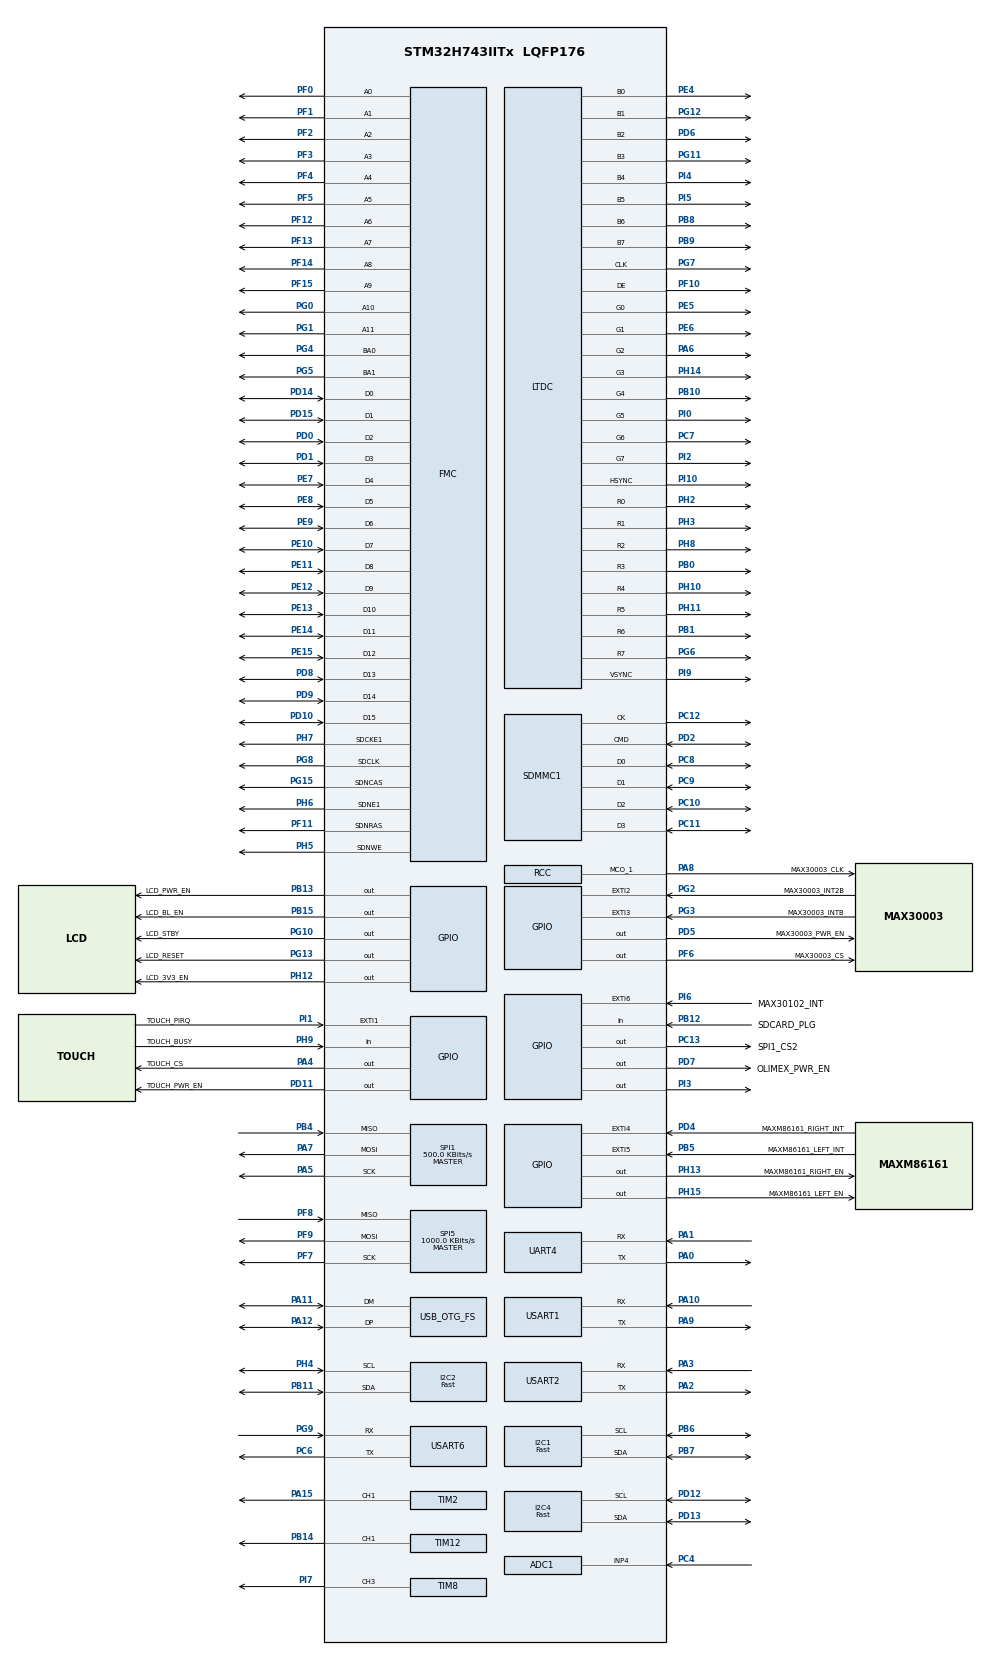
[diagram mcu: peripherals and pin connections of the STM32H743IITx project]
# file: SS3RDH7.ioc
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ADC1.Channel-1\#ChannelRegularConversion=ADC_CHANNEL_4
ADC1.ClockPrescaler=ADC_CLOCK_ASYNC_DIV128
ADC1.EOCSelection=ADC_EOC_SEQ_CONV
ADC1.ExternalTrigConv=ADC_EXTERNALTRIG_T3_TRGO
ADC1.NbrOfConversionFlag=1
ADC1.OffsetNumber-1\#ChannelRegularConversion=ADC_OFFSET_NONE
ADC1.OffsetSignedSaturation-1\#ChannelRegularConversion=DISABLE
ADC1.Rank-1\#ChannelRegularConversion=1
ADC1.SamplingTime-1\#ChannelRegularConversion=ADC_SAMPLETIME_1CYCLE_5
ADC1.master=1
Bdma.I2C4_RX.0.Direction=DMA_PERIPH_TO_MEMORY
Bdma.I2C4_RX.0.EventEnable=DISABLE
Bdma.I2C4_RX.0.Instance=BDMA_Channel0
Bdma.I2C4_RX.0.MemDataAlignment=DMA_MDATAALIGN_BYTE
Bdma.I2C4_RX.0.MemInc=DMA_MINC_ENABLE
Bdma.I2C4_RX.0.Mode=DMA_NORMAL
Bdma.I2C4_RX.0.PeriphDataAlignment=DMA_PDATAALIGN_BYTE
Bdma.I2C4_RX.0.PeriphInc=DMA_PINC_DISABLE
Bdma.I2C4_RX.0.Polarity=HAL_DMAMUX_REQ_GEN_RISING
Bdma.I2C4_RX.0.Priority=DMA_PRIORITY_MEDIUM
Bdma.I2C4_RX.0.RequestNumber=1
Bdma.I2C4_RX.0.SignalID=NONE
Bdma.I2C4_RX.0.SyncEnable=DISABLE
Bdma.I2C4_RX.0.SyncPolarity=HAL_DMAMUX_SYNC_NO_EVENT
Bdma.I2C4_RX.0.SyncRequestNumber=1
Bdma.I2C4_RX.0.SyncSignalID=NONE
Bdma.I2C4_TX.1.Direction=DMA_MEMORY_TO_PERIPH
Bdma.I2C4_TX.1.EventEnable=DISABLE
Bdma.I2C4_TX.1.Instance=BDMA_Channel1
Bdma.I2C4_TX.1.MemDataAlignment=DMA_MDATAALIGN_BYTE
Bdma.I2C4_TX.1.MemInc=DMA_MINC_ENABLE
Bdma.I2C4_TX.1.Mode=DMA_NORMAL
Bdma.I2C4_TX.1.PeriphDataAlignment=DMA_PDATAALIGN_BYTE
Bdma.I2C4_TX.1.PeriphInc=DMA_PINC_DISABLE
Bdma.I2C4_TX.1.Polarity=HAL_DMAMUX_REQ_GEN_RISING
Bdma.I2C4_TX.1.Priority=DMA_PRIORITY_MEDIUM
Bdma.I2C4_TX.1.RequestNumber=1
Bdma.I2C4_TX.1.SignalID=NONE
Bdma.I2C4_TX.1.SyncEnable=DISABLE
Bdma.I2C4_TX.1.SyncPolarity=HAL_DMAMUX_SYNC_NO_EVENT
Bdma.I2C4_TX.1.SyncRequestNumber=1
Bdma.I2C4_TX.1.SyncSignalID=NONE
Bdma.Request0=I2C4_RX
Bdma.Request1=I2C4_TX
Bdma.RequestsNb=2
CORTEX_M7.CPU_DCache=Enabled
CORTEX_M7.CPU_ICache=Enabled
DMA2D.InputAlphaForeground=255
Dma.I2C1_RX.0.Direction=DMA_PERIPH_TO_MEMORY
Dma.I2C1_RX.0.EventEnable=DISABLE
Dma.I2C1_RX.0.FIFOMode=DMA_FIFOMODE_DISABLE
Dma.I2C1_RX.0.Instance=DMA1_Stream0
Dma.I2C1_RX.0.MemDataAlignment=DMA_MDATAALIGN_BYTE
Dma.I2C1_RX.0.MemInc=DMA_MINC_ENABLE
Dma.I2C1_RX.0.Mode=DMA_NORMAL
Dma.I2C1_RX.0.PeriphDataAlignment=DMA_PDATAALIGN_BYTE
Dma.I2C1_RX.0.PeriphInc=DMA_PINC_DISABLE
Dma.I2C1_RX.0.Polarity=HAL_DMAMUX_REQ_GEN_RISING
Dma.I2C1_RX.0.Priority=DMA_PRIORITY_MEDIUM
Dma.I2C1_RX.0.RequestNumber=1
Dma.I2C1_RX.0.SignalID=NONE
Dma.I2C1_RX.0.SyncEnable=DISABLE
Dma.I2C1_RX.0.SyncPolarity=HAL_DMAMUX_SYNC_NO_EVENT
Dma.I2C1_RX.0.SyncRequestNumber=1
Dma.I2C1_RX.0.SyncSignalID=NONE
Dma.I2C1_TX.1.Direction=DMA_MEMORY_TO_PERIPH
Dma.I2C1_TX.1.EventEnable=DISABLE
Dma.I2C1_TX.1.FIFOMode=DMA_FIFOMODE_DISABLE
Dma.I2C1_TX.1.Instance=DMA1_Stream1
Dma.I2C1_TX.1.MemDataAlignment=DMA_MDATAALIGN_BYTE
Dma.I2C1_TX.1.MemInc=DMA_MINC_ENABLE
Dma.I2C1_TX.1.Mode=DMA_NORMAL
Dma.I2C1_TX.1.PeriphDataAlignment=DMA_PDATAALIGN_BYTE
Dma.I2C1_TX.1.PeriphInc=DMA_PINC_DISABLE
Dma.I2C1_TX.1.Polarity=HAL_DMAMUX_REQ_GEN_RISING
Dma.I2C1_TX.1.Priority=DMA_PRIORITY_MEDIUM
Dma.I2C1_TX.1.RequestNumber=1
Dma.I2C1_TX.1.SignalID=NONE
Dma.I2C1_TX.1.SyncEnable=DISABLE
Dma.I2C1_TX.1.SyncPolarity=HAL_DMAMUX_SYNC_NO_EVENT
Dma.I2C1_TX.1.SyncRequestNumber=1
Dma.I2C1_TX.1.SyncSignalID=NONE
Dma.I2C2_RX.2.Direction=DMA_PERIPH_TO_MEMORY
Dma.I2C2_RX.2.EventEnable=DISABLE
Dma.I2C2_RX.2.FIFOMode=DMA_FIFOMODE_DISABLE
Dma.I2C2_RX.2.Instance=DMA1_Stream2
Dma.I2C2_RX.2.MemDataAlignment=DMA_MDATAALIGN_BYTE
Dma.I2C2_RX.2.MemInc=DMA_MINC_ENABLE
Dma.I2C2_RX.2.Mode=DMA_NORMAL
Dma.I2C2_RX.2.PeriphDataAlignment=DMA_PDATAALIGN_BYTE
Dma.I2C2_RX.2.PeriphInc=DMA_PINC_DISABLE
Dma.I2C2_RX.2.Polarity=HAL_DMAMUX_REQ_GEN_RISING
Dma.I2C2_RX.2.Priority=DMA_PRIORITY_MEDIUM
Dma.I2C2_RX.2.RequestNumber=1
Dma.I2C2_RX.2.SignalID=NONE
Dma.I2C2_RX.2.SyncEnable=DISABLE
Dma.I2C2_RX.2.SyncPolarity=HAL_DMAMUX_SYNC_NO_EVENT
Dma.I2C2_RX.2.SyncRequestNumber=1
Dma.I2C2_RX.2.SyncSignalID=NONE
Dma.I2C2_TX.3.Direction=DMA_MEMORY_TO_PERIPH
Dma.I2C2_TX.3.EventEnable=DISABLE
Dma.I2C2_TX.3.FIFOMode=DMA_FIFOMODE_DISABLE
Dma.I2C2_TX.3.Instance=DMA1_Stream3
Dma.I2C2_TX.3.MemDataAlignment=DMA_MDATAALIGN_BYTE
Dma.I2C2_TX.3.MemInc=DMA_MINC_ENABLE
Dma.I2C2_TX.3.Mode=DMA_NORMAL
Dma.I2C2_TX.3.PeriphDataAlignment=DMA_PDATAALIGN_BYTE
Dma.I2C2_TX.3.PeriphInc=DMA_PINC_DISABLE
Dma.I2C2_TX.3.Polarity=HAL_DMAMUX_REQ_GEN_RISING
Dma.I2C2_TX.3.Priority=DMA_PRIORITY_MEDIUM
Dma.I2C2_TX.3.RequestNumber=1
Dma.I2C2_TX.3.SignalID=NONE
Dma.I2C2_TX.3.SyncEnable=DISABLE
Dma.I2C2_TX.3.SyncPolarity=HAL_DMAMUX_SYNC_NO_EVENT
Dma.I2C2_TX.3.SyncRequestNumber=1
Dma.I2C2_TX.3.SyncSignalID=NONE
Dma.Request0=I2C1_RX
Dma.Request1=I2C1_TX
Dma.Request10=USART6_RX
Dma.Request11=USART6_TX
Dma.Request12=SPI1_RX
Dma.Request13=SPI1_TX
Dma.Request14=SPI5_RX
Dma.Request15=SPI5_TX
Dma.Request2=I2C2_RX
Dma.Request3=I2C2_TX
Dma.Request4=UART4_RX
Dma.Request5=UART4_TX
Dma.Request6=USART2_RX
Dma.Request7=USART2_TX
Dma.Request8=USART1_RX
Dma.Request9=USART1_TX
Dma.SPI1_RX.12.Direction=DMA_PERIPH_TO_MEMORY
Dma.SPI1_RX.12.EventEnable=DISABLE
Dma.SPI1_RX.12.FIFOMode=DMA_FIFOMODE_DISABLE
Dma.SPI1_RX.12.Instance=DMA2_Stream4
Dma.SPI1_RX.12.MemDataAlignment=DMA_MDATAALIGN_BYTE
Dma.SPI1_RX.12.MemInc=DMA_MINC_ENABLE
Dma.SPI1_RX.12.Mode=DMA_NORMAL
Dma.SPI1_RX.12.PeriphDataAlignment=DMA_PDATAALIGN_BYTE
Dma.SPI1_RX.12.PeriphInc=DMA_PINC_DISABLE
Dma.SPI1_RX.12.Polarity=HAL_DMAMUX_REQ_GEN_RISING
Dma.SPI1_RX.12.Priority=DMA_PRIORITY_MEDIUM
Dma.SPI1_RX.12.RequestNumber=1
Dma.SPI1_RX.12.SignalID=NONE
Dma.SPI1_RX.12.SyncEnable=DISABLE
Dma.SPI1_RX.12.SyncPolarity=HAL_DMAMUX_SYNC_NO_EVENT
Dma.SPI1_RX.12.SyncRequestNumber=1
Dma.SPI1_RX.12.SyncSignalID=NONE
Dma.SPI1_TX.13.Direction=DMA_MEMORY_TO_PERIPH
Dma.SPI1_TX.13.EventEnable=DISABLE
Dma.SPI1_TX.13.FIFOMode=DMA_FIFOMODE_DISABLE
Dma.SPI1_TX.13.Instance=DMA2_Stream5
Dma.SPI1_TX.13.MemDataAlignment=DMA_MDATAALIGN_BYTE
Dma.SPI1_TX.13.MemInc=DMA_MINC_ENABLE
Dma.SPI1_TX.13.Mode=DMA_NORMAL
Dma.SPI1_TX.13.PeriphDataAlignment=DMA_PDATAALIGN_BYTE
Dma.SPI1_TX.13.PeriphInc=DMA_PINC_DISABLE
Dma.SPI1_TX.13.Polarity=HAL_DMAMUX_REQ_GEN_RISING
Dma.SPI1_TX.13.Priority=DMA_PRIORITY_MEDIUM
Dma.SPI1_TX.13.RequestNumber=1
Dma.SPI1_TX.13.SignalID=NONE
Dma.SPI1_TX.13.SyncEnable=DISABLE
Dma.SPI1_TX.13.SyncPolarity=HAL_DMAMUX_SYNC_NO_EVENT
Dma.SPI1_TX.13.SyncRequestNumber=1
Dma.SPI1_TX.13.SyncSignalID=NONE
Dma.SPI5_RX.14.Direction=DMA_PERIPH_TO_MEMORY
Dma.SPI5_RX.14.EventEnable=DISABLE
Dma.SPI5_RX.14.FIFOMode=DMA_FIFOMODE_DISABLE
Dma.SPI5_RX.14.Instance=DMA2_Stream6
Dma.SPI5_RX.14.MemDataAlignment=DMA_MDATAALIGN_BYTE
Dma.SPI5_RX.14.MemInc=DMA_MINC_ENABLE
Dma.SPI5_RX.14.Mode=DMA_NORMAL
Dma.SPI5_RX.14.PeriphDataAlignment=DMA_PDATAALIGN_BYTE
Dma.SPI5_RX.14.PeriphInc=DMA_PINC_DISABLE
Dma.SPI5_RX.14.Polarity=HAL_DMAMUX_REQ_GEN_RISING
Dma.SPI5_RX.14.Priority=DMA_PRIORITY_MEDIUM
Dma.SPI5_RX.14.RequestNumber=1
Dma.SPI5_RX.14.SignalID=NONE
Dma.SPI5_RX.14.SyncEnable=DISABLE
Dma.SPI5_RX.14.SyncPolarity=HAL_DMAMUX_SYNC_NO_EVENT
Dma.SPI5_RX.14.SyncRequestNumber=1
Dma.SPI5_RX.14.SyncSignalID=NONE
Dma.SPI5_TX.15.Direction=DMA_MEMORY_TO_PERIPH
Dma.SPI5_TX.15.EventEnable=DISABLE
Dma.SPI5_TX.15.FIFOMode=DMA_FIFOMODE_DISABLE
Dma.SPI5_TX.15.Instance=DMA2_Stream7
Dma.SPI5_TX.15.MemDataAlignment=DMA_MDATAALIGN_BYTE
Dma.SPI5_TX.15.MemInc=DMA_MINC_ENABLE
Dma.SPI5_TX.15.Mode=DMA_NORMAL
Dma.SPI5_TX.15.PeriphDataAlignment=DMA_PDATAALIGN_BYTE
Dma.SPI5_TX.15.PeriphInc=DMA_PINC_DISABLE
Dma.SPI5_TX.15.Polarity=HAL_DMAMUX_REQ_GEN_RISING
Dma.SPI5_TX.15.Priority=DMA_PRIORITY_MEDIUM
Dma.SPI5_TX.15.RequestNumber=1
Dma.SPI5_TX.15.SignalID=NONE
Dma.SPI5_TX.15.SyncEnable=DISABLE
Dma.SPI5_TX.15.SyncPolarity=HAL_DMAMUX_SYNC_NO_EVENT
Dma.SPI5_TX.15.SyncRequestNumber=1
Dma.SPI5_TX.15.SyncSignalID=NONE
Dma.UART4_RX.4.Direction=DMA_PERIPH_TO_MEMORY
Dma.UART4_RX.4.EventEnable=DISABLE
Dma.UART4_RX.4.FIFOMode=DMA_FIFOMODE_DISABLE
Dma.UART4_RX.4.Instance=DMA1_Stream4
Dma.UART4_RX.4.MemDataAlignment=DMA_MDATAALIGN_BYTE
Dma.UART4_RX.4.MemInc=DMA_MINC_ENABLE
Dma.UART4_RX.4.Mode=DMA_NORMAL
Dma.UART4_RX.4.PeriphDataAlignment=DMA_PDATAALIGN_BYTE
Dma.UART4_RX.4.PeriphInc=DMA_PINC_DISABLE
Dma.UART4_RX.4.Polarity=HAL_DMAMUX_REQ_GEN_RISING
Dma.UART4_RX.4.Priority=DMA_PRIORITY_LOW
Dma.UART4_RX.4.RequestNumber=1
Dma.UART4_RX.4.SignalID=NONE
Dma.UART4_RX.4.SyncEnable=DISABLE
Dma.UART4_RX.4.SyncPolarity=HAL_DMAMUX_SYNC_NO_EVENT
Dma.UART4_RX.4.SyncRequestNumber=1
Dma.UART4_RX.4.SyncSignalID=NONE
Dma.UART4_TX.5.Direction=DMA_MEMORY_TO_PERIPH
Dma.UART4_TX.5.EventEnable=DISABLE
Dma.UART4_TX.5.FIFOMode=DMA_FIFOMODE_DISABLE
Dma.UART4_TX.5.Instance=DMA1_Stream5
Dma.UART4_TX.5.MemDataAlignment=DMA_MDATAALIGN_BYTE
Dma.UART4_TX.5.MemInc=DMA_MINC_ENABLE
Dma.UART4_TX.5.Mode=DMA_NORMAL
Dma.UART4_TX.5.PeriphDataAlignment=DMA_PDATAALIGN_BYTE
Dma.UART4_TX.5.PeriphInc=DMA_PINC_DISABLE
Dma.UART4_TX.5.Polarity=HAL_DMAMUX_REQ_GEN_RISING
Dma.UART4_TX.5.Priority=DMA_PRIORITY_LOW
Dma.UART4_TX.5.RequestNumber=1
Dma.UART4_TX.5.SignalID=NONE
Dma.UART4_TX.5.SyncEnable=DISABLE
Dma.UART4_TX.5.SyncPolarity=HAL_DMAMUX_SYNC_NO_EVENT
Dma.UART4_TX.5.SyncRequestNumber=1
Dma.UART4_TX.5.SyncSignalID=NONE
Dma.USART1_RX.8.Direction=DMA_PERIPH_TO_MEMORY
Dma.USART1_RX.8.EventEnable=DISABLE
Dma.USART1_RX.8.FIFOMode=DMA_FIFOMODE_DISABLE
Dma.USART1_RX.8.Instance=DMA2_Stream0
Dma.USART1_RX.8.MemDataAlignment=DMA_MDATAALIGN_BYTE
Dma.USART1_RX.8.MemInc=DMA_MINC_ENABLE
Dma.USART1_RX.8.Mode=DMA_NORMAL
Dma.USART1_RX.8.PeriphDataAlignment=DMA_PDATAALIGN_BYTE
Dma.USART1_RX.8.PeriphInc=DMA_PINC_DISABLE
Dma.USART1_RX.8.Polarity=HAL_DMAMUX_REQ_GEN_RISING
Dma.USART1_RX.8.Priority=DMA_PRIORITY_MEDIUM
Dma.USART1_RX.8.RequestNumber=1
Dma.USART1_RX.8.SignalID=NONE
Dma.USART1_RX.8.SyncEnable=DISABLE
Dma.USART1_RX.8.SyncPolarity=HAL_DMAMUX_SYNC_NO_EVENT
Dma.USART1_RX.8.SyncRequestNumber=1
Dma.USART1_RX.8.SyncSignalID=NONE
Dma.USART1_TX.9.Direction=DMA_MEMORY_TO_PERIPH
Dma.USART1_TX.9.EventEnable=DISABLE
Dma.USART1_TX.9.FIFOMode=DMA_FIFOMODE_DISABLE
Dma.USART1_TX.9.Instance=DMA2_Stream1
Dma.USART1_TX.9.MemDataAlignment=DMA_MDATAALIGN_BYTE
Dma.USART1_TX.9.MemInc=DMA_MINC_ENABLE
Dma.USART1_TX.9.Mode=DMA_NORMAL
Dma.USART1_TX.9.PeriphDataAlignment=DMA_PDATAALIGN_BYTE
Dma.USART1_TX.9.PeriphInc=DMA_PINC_DISABLE
Dma.USART1_TX.9.Polarity=HAL_DMAMUX_REQ_GEN_RISING
Dma.USART1_TX.9.Priority=DMA_PRIORITY_MEDIUM
Dma.USART1_TX.9.RequestNumber=1
Dma.USART1_TX.9.SignalID=NONE
Dma.USART1_TX.9.SyncEnable=DISABLE
Dma.USART1_TX.9.SyncPolarity=HAL_DMAMUX_SYNC_NO_EVENT
Dma.USART1_TX.9.SyncRequestNumber=1
Dma.USART1_TX.9.SyncSignalID=NONE
Dma.USART2_RX.6.Direction=DMA_PERIPH_TO_MEMORY
Dma.USART2_RX.6.EventEnable=DISABLE
Dma.USART2_RX.6.FIFOMode=DMA_FIFOMODE_DISABLE
Dma.USART2_RX.6.Instance=DMA1_Stream6
Dma.USART2_RX.6.MemDataAlignment=DMA_MDATAALIGN_BYTE
Dma.USART2_RX.6.MemInc=DMA_MINC_ENABLE
Dma.USART2_RX.6.Mode=DMA_NORMAL
Dma.USART2_RX.6.PeriphDataAlignment=DMA_PDATAALIGN_BYTE
Dma.USART2_RX.6.PeriphInc=DMA_PINC_DISABLE
Dma.USART2_RX.6.Polarity=HAL_DMAMUX_REQ_GEN_RISING
Dma.USART2_RX.6.Priority=DMA_PRIORITY_LOW
Dma.USART2_RX.6.RequestNumber=1
Dma.USART2_RX.6.SignalID=NONE
Dma.USART2_RX.6.SyncEnable=DISABLE
Dma.USART2_RX.6.SyncPolarity=HAL_DMAMUX_SYNC_NO_EVENT
Dma.USART2_RX.6.SyncRequestNumber=1
Dma.USART2_RX.6.SyncSignalID=NONE
Dma.USART2_TX.7.Direction=DMA_MEMORY_TO_PERIPH
Dma.USART2_TX.7.EventEnable=DISABLE
Dma.USART2_TX.7.FIFOMode=DMA_FIFOMODE_DISABLE
Dma.USART2_TX.7.Instance=DMA1_Stream7
Dma.USART2_TX.7.MemDataAlignment=DMA_MDATAALIGN_BYTE
Dma.USART2_TX.7.MemInc=DMA_MINC_ENABLE
Dma.USART2_TX.7.Mode=DMA_NORMAL
Dma.USART2_TX.7.PeriphDataAlignment=DMA_PDATAALIGN_BYTE
Dma.USART2_TX.7.PeriphInc=DMA_PINC_DISABLE
Dma.USART2_TX.7.Polarity=HAL_DMAMUX_REQ_GEN_RISING
Dma.USART2_TX.7.Priority=DMA_PRIORITY_LOW
Dma.USART2_TX.7.RequestNumber=1
Dma.USART2_TX.7.SignalID=NONE
Dma.USART2_TX.7.SyncEnable=DISABLE
Dma.USART2_TX.7.SyncPolarity=HAL_DMAMUX_SYNC_NO_EVENT
Dma.USART2_TX.7.SyncRequestNumber=1
Dma.USART2_TX.7.SyncSignalID=NONE
Dma.USART6_RX.10.Direction=DMA_PERIPH_TO_MEMORY
Dma.USART6_RX.10.EventEnable=DISABLE
Dma.USART6_RX.10.FIFOMode=DMA_FIFOMODE_DISABLE
Dma.USART6_RX.10.Instance=DMA2_Stream2
Dma.USART6_RX.10.MemDataAlignment=DMA_MDATAALIGN_BYTE
Dma.USART6_RX.10.MemInc=DMA_MINC_ENABLE
Dma.USART6_RX.10.Mode=DMA_NORMAL
Dma.USART6_RX.10.PeriphDataAlignment=DMA_PDATAALIGN_BYTE
Dma.USART6_RX.10.PeriphInc=DMA_PINC_DISABLE
Dma.USART6_RX.10.Polarity=HAL_DMAMUX_REQ_GEN_RISING
Dma.USART6_RX.10.Priority=DMA_PRIORITY_LOW
Dma.USART6_RX.10.RequestNumber=1
Dma.USART6_RX.10.SignalID=NONE
Dma.USART6_RX.10.SyncEnable=DISABLE
Dma.USART6_RX.10.SyncPolarity=HAL_DMAMUX_SYNC_NO_EVENT
Dma.USART6_RX.10.SyncRequestNumber=1
Dma.USART6_RX.10.SyncSignalID=NONE
Dma.USART6_TX.11.Direction=DMA_MEMORY_TO_PERIPH
Dma.USART6_TX.11.EventEnable=DISABLE
Dma.USART6_TX.11.FIFOMode=DMA_FIFOMODE_DISABLE
Dma.USART6_TX.11.Instance=DMA2_Stream3
Dma.USART6_TX.11.MemDataAlignment=DMA_MDATAALIGN_BYTE
Dma.USART6_TX.11.MemInc=DMA_MINC_ENABLE
Dma.USART6_TX.11.Mode=DMA_NORMAL
Dma.USART6_TX.11.PeriphDataAlignment=DMA_PDATAALIGN_BYTE
Dma.USART6_TX.11.PeriphInc=DMA_PINC_DISABLE
Dma.USART6_TX.11.Polarity=HAL_DMAMUX_REQ_GEN_RISING
Dma.USART6_TX.11.Priority=DMA_PRIORITY_LOW
Dma.USART6_TX.11.RequestNumber=1
Dma.USART6_TX.11.SignalID=NONE
Dma.USART6_TX.11.SyncEnable=DISABLE
Dma.USART6_TX.11.SyncPolarity=HAL_DMAMUX_SYNC_NO_EVENT
Dma.USART6_TX.11.SyncRequestNumber=1
Dma.USART6_TX.11.SyncSignalID=NONE
FATFS.BSP.number=1
FATFS._MAX_SS=4096
FATFS0.BSP.STBoard=false
FATFS0.BSP.api=Unknown
FATFS0.BSP.i2caddr=0
FATFS0.BSP.instance=PB12
FATFS0.BSP.ip=GPIO
FATFS0.BSP.mode=Input
FATFS0.BSP.name=Detect_SDIO
FATFS0.BSP.solution=PB12
FMC.CASLatency1=FMC_SDRAM_CAS_LATENCY_3
FMC.ExitSelfRefreshDelay1=7
FMC.LoadToActiveDelay1=2
FMC.RCDDelay1=2
FMC.RPDelay1=2
FMC.RPDelay2=2
FMC.ReadBurst1=FMC_SDRAM_RBURST_ENABLE
FMC.ReadBurst2=FMC_SDRAM_RBURST_ENABLE
FMC.ReadPipeDelay1=FMC_SDRAM_RPIPE_DELAY_2
FMC.ReadPipeDelay2=FMC_SDRAM_RPIPE_DELAY_2
FMC.RowCycleDelay1=6
FMC.RowCycleDelay2=6
FMC.SDClockPeriod1=FMC_SDRAM_CLOCK_PERIOD_2
FMC.SDClockPeriod2=FMC_SDRAM_CLOCK_PERIOD_2
FMC.SelfRefreshTime1=4
FMC.WriteRecoveryTime1=2
FREERTOS.Tasks01=defaultTask,24,1024,StartDefaultTask,Default,NULL,Dynamic,NULL,NULL;touchTask,24,1024,StartTouchTask,Default,NULL,Dynamic,NULL,NULL;touchIRQTask,24,1024,StartTouchIRQTask,Default,NULL,Dynamic,NULL,NULL;max30003Task,24,1024,StartMAX30003Task,Default,NULL,Dynamic,NULL,NULL;max30003IRQTask,24,1024,StartMAX30003IRQTask,Default,NULL,Dynamic,NULL,NULL;max30102Task,8,1024,StartMAX30102Task,Default,NULL,Dynamic,NULL,NULL;max30102IRQTask,24,1024,StartMAX30102IRQTask,Default,NULL,Dynamic,NULL,NULL;maxm86161RTask,24,1024,StartMAXM86161RTask,Default,NULL,Dynamic,NULL,NULL;maxm86161IRTask,24,1024,StartMAXM86161IRQRTask,Default,NULL,Dynamic,NULL,NULL;maxm86161LTask,24,1024,StartMAXM86161LTask,Default,NULL,Dynamic,NULL,NULL;maxm86161ILTask,24,1024,StartMAXM86161IRQLTask,Default,NULL,Dynamic,NULL,NULL;i2c1TxTask,24,1024,StartI2C1TxTask,Default,NULL,Dynamic,NULL,NULL;i2c1RxTask,24,1024,StartI2C1RxTask,Default,NULL,Dynamic,NULL,NULL;i2c1ErrorTask,24,1024,StartI2C1ErrorTask,Default,NULL,Dynamic,NULL,NULL;i2c2TxTask,24,1024,StartI2C2TxTask,Default,NULL,Dynamic,NULL,NULL;i2c2RxTask,24,1024,StartI2C2RxTask,Default,NULL,Dynamic,NULL,NULL;i2c2ErrorTask,24,1024,StartI2C2ErrorTask,Default,NULL,Dynamic,NULL,NULL;debugTask,24,1024,StartDebugTask,Default,NULL,Dynamic,NULL,NULL;fatFsTask,24,1024,StartFatFsTask,Default,NULL,Dynamic,NULL,NULL;usbTask,24,1024,StartUsbTask,Default,NULL,Dynamic,NULL,NULL;usbDmaTxTask,24,1024,StartUsbDmaTxTask,Default,NULL,Dynamic,NULL,NULL;usbDmaRxTask,24,1024,StartUsbDmaRxTask,Default,NULL,Dynamic,NULL,NULL;i2c4TxTask,24,1024,StartI2C4TxTask,Default,NULL,Dynamic,NULL,NULL;i2c4RxTask,8,1024,StartI2C4RxTask,Default,NULL,Dynamic,NULL,NULL;i2c4ErrorTask,8,1024,StartI2C4ErrorTask,Default,NULL,Dynamic,NULL,NULL
FREERTOS.configENABLE_FPU=1
FREERTOS.configMINIMAL_STACK_SIZE=1024
FREERTOS.configTOTAL_HEAP_SIZE=159744
FREERTOS.configUSE_DAEMON_TASK_STARTUP_HOOK=1
FREERTOS.configUSE_IDLE_HOOK=1
FREERTOS.configUSE_MALLOC_FAILED_HOOK=1
FREERTOS.configUSE_STATS_FORMATTING_FUNCTIONS=1
FREERTOS.configUSE_TICK_HOOK=1
I2C1.I2C_Speed_Mode=I2C_Fast
I2C1.Timing=0x00B03FDB
I2C2.I2C_Speed_Mode=I2C_Fast
I2C2.Timing=0x00B03FDB
I2C4.I2C_Speed_Mode=I2C_Fast
I2C4.Timing=0x00B03FDB
LTDC.ActiveW=800
LTDC.Alpha0_L0=255
LTDC.Alpha0_L1=255
LTDC.Alpha_L0=255
LTDC.Alpha_L1=255
LTDC.FBStartAdress_L0=0xD0000000
LTDC.FBStartAdress_L1=0xD0119400
LTDC.HBP=40
LTDC.HFP=40
LTDC.HSync=48
LTDC.ImageHeight_L0=480
LTDC.ImageHeight_L1=480
LTDC.ImageWidth_L0=800
LTDC.Layers=0
LTDC.PixelFormat_L0=LTDC_PIXEL_FORMAT_RGB888
LTDC.VBP=29
LTDC.VFP=13
LTDC.VSync=3
LTDC.WindowX1_L0=800
LTDC.WindowX1_L1=800
LTDC.WindowY1_L0=480
LTDC.WindowY1_L1=480
Mcu.Family=STM32H7
Mcu.Name=STM32H743IITx
Mcu.Package=LQFP176
NVIC.ADC_IRQn=true\:5\:0\:false\:false\:true\:true\:true\:true
NVIC.BDMA_Channel0_IRQn=true\:5\:0\:false\:false\:true\:true\:false\:true
NVIC.BDMA_Channel1_IRQn=true\:5\:0\:false\:false\:true\:true\:false\:true
NVIC.DMA1_Stream0_IRQn=true\:5\:0\:false\:false\:true\:true\:false\:true
NVIC.DMA1_Stream1_IRQn=true\:5\:0\:false\:false\:true\:true\:false\:true
NVIC.DMA1_Stream2_IRQn=true\:5\:0\:false\:false\:true\:true\:false\:true
NVIC.DMA1_Stream3_IRQn=true\:5\:0\:false\:false\:true\:true\:false\:true
NVIC.DMA1_Stream4_IRQn=true\:5\:0\:false\:false\:true\:true\:false\:true
NVIC.DMA1_Stream5_IRQn=true\:5\:0\:false\:false\:true\:true\:false\:true
NVIC.DMA1_Stream6_IRQn=true\:5\:0\:false\:false\:true\:true\:false\:true
NVIC.DMA1_Stream7_IRQn=true\:5\:0\:false\:false\:true\:true\:false\:true
NVIC.DMA2D_IRQn=true\:5\:0\:false\:false\:true\:false\:true\:true
NVIC.DMA2_Stream0_IRQn=true\:5\:0\:false\:false\:true\:true\:false\:true
NVIC.DMA2_Stream1_IRQn=true\:5\:0\:false\:false\:true\:true\:false\:true
NVIC.DMA2_Stream2_IRQn=true\:5\:0\:false\:false\:true\:true\:false\:true
NVIC.DMA2_Stream3_IRQn=true\:5\:0\:false\:false\:true\:true\:false\:true
NVIC.DMA2_Stream4_IRQn=true\:5\:0\:false\:false\:true\:true\:false\:true
NVIC.DMA2_Stream5_IRQn=true\:5\:0\:false\:false\:true\:true\:false\:true
NVIC.DMA2_Stream6_IRQn=true\:5\:0\:false\:false\:true\:true\:false\:true
NVIC.DMA2_Stream7_IRQn=true\:5\:0\:false\:false\:true\:true\:false\:true
NVIC.EXTI1_IRQn=true\:5\:0\:false\:false\:true\:true\:true\:true
NVIC.EXTI2_IRQn=true\:5\:0\:false\:false\:true\:true\:true\:true
NVIC.EXTI3_IRQn=true\:5\:0\:false\:false\:true\:true\:true\:true
NVIC.EXTI4_IRQn=true\:5\:0\:false\:false\:true\:true\:true\:true
NVIC.EXTI9_5_IRQn=true\:5\:0\:false\:false\:true\:true\:true\:true
NVIC.FPU_IRQn=true\:5\:0\:false\:false\:true\:true\:true\:false
NVIC.I2C1_ER_IRQn=true\:5\:0\:false\:false\:true\:true\:true\:true
NVIC.I2C1_EV_IRQn=true\:5\:0\:false\:false\:true\:true\:true\:true
NVIC.I2C2_ER_IRQn=true\:5\:0\:false\:false\:true\:true\:true\:true
NVIC.I2C2_EV_IRQn=true\:5\:0\:false\:false\:true\:true\:true\:true
NVIC.I2C4_ER_IRQn=true\:5\:0\:false\:false\:true\:true\:true\:true
NVIC.I2C4_EV_IRQn=true\:5\:0\:false\:false\:true\:true\:true\:true
NVIC.JPEG_IRQn=true\:5\:0\:false\:false\:true\:true\:true\:true
NVIC.LTDC_ER_IRQn=true\:5\:0\:false\:false\:true\:true\:true\:true
NVIC.LTDC_IRQn=true\:5\:0\:false\:false\:true\:true\:true\:true
NVIC.OTG_FS_EP1_IN_IRQn=true\:5\:0\:false\:false\:true\:true\:true\:true
NVIC.OTG_FS_EP1_OUT_IRQn=true\:5\:0\:false\:false\:true\:true\:true\:true
NVIC.OTG_FS_IRQn=true\:5\:0\:false\:false\:true\:true\:false\:true
NVIC.PriorityGroup=NVIC_PRIORITYGROUP_4
NVIC.SDMMC1_IRQn=true\:5\:0\:false\:false\:true\:true\:true\:true
NVIC.SPI1_IRQn=true\:5\:0\:false\:false\:true\:false\:false\:true
NVIC.SPI5_IRQn=true\:5\:0\:false\:false\:true\:false\:false\:true
NVIC.TIM6_DAC_IRQn=true\:0\:0\:false\:false\:true\:false\:false\:true
NVIC.TimeBase=TIM6_DAC_IRQn
NVIC.TimeBaseIP=TIM6
NVIC.UART4_IRQn=true\:5\:0\:false\:false\:true\:true\:true\:true
NVIC.USART1_IRQn=true\:5\:0\:false\:false\:true\:true\:true\:true
NVIC.USART2_IRQn=true\:5\:0\:false\:false\:true\:true\:true\:true
NVIC.USART6_IRQn=true\:5\:0\:false\:false\:true\:true\:true\:true
PA0.GPIO_Speed=GPIO_SPEED_FREQ_VERY_HIGH
PA0.Mode=Asynchronous
PA0.Signal=UART4_TX
PA1.GPIO_Speed=GPIO_SPEED_FREQ_VERY_HIGH
PA1.Mode=Asynchronous
PA1.Signal=UART4_RX
PA10.GPIO_Speed=GPIO_SPEED_FREQ_VERY_HIGH
PA10.Mode=Asynchronous
PA10.Signal=USART1_RX
PA11.GPIO_Speed=GPIO_SPEED_FREQ_VERY_HIGH
PA11.Mode=Device_Only
PA11.Signal=USB_OTG_FS_DM
PA12.GPIO_Speed=GPIO_SPEED_FREQ_VERY_HIGH
PA12.Mode=Device_Only
PA12.Signal=USB_OTG_FS_DP
PA13\ (JTMS/SWDIO).Mode=Trace_Asynchronous_SW
PA13\ (JTMS/SWDIO).Signal=DEBUG_JTMS-SWDIO
PA14\ (JTCK/SWCLK).Mode=Trace_Asynchronous_SW
PA14\ (JTCK/SWCLK).Signal=DEBUG_JTCK-SWCLK
PA15\ (JTDI).Signal=S_TIM2_CH1
PA2.GPIO_Speed=GPIO_SPEED_FREQ_VERY_HIGH
PA2.Mode=Asynchronous
PA2.Signal=USART2_TX
PA3.GPIO_Speed=GPIO_SPEED_FREQ_VERY_HIGH
PA3.Mode=Asynchronous
PA3.Signal=USART2_RX
PA4.GPIO_Label=TOUCH_CS
PA4.GPIO_PuPd=GPIO_PULLUP
PA4.GPIO_Speed=GPIO_SPEED_FREQ_VERY_HIGH
PA4.PinState=GPIO_PIN_SET
PA4.Signal=GPIO_Output
PA5.GPIO_PuPd=GPIO_PULLUP
PA5.GPIO_Speed=GPIO_SPEED_FREQ_VERY_HIGH
PA5.Mode=Full_Duplex_Master
PA5.Signal=SPI1_SCK
PA6.GPIO_Speed=GPIO_SPEED_FREQ_VERY_HIGH
PA6.Mode=RGB888
PA6.Signal=LTDC_G2
PA7.GPIO_PuPd=GPIO_PULLUP
PA7.GPIO_Speed=GPIO_SPEED_FREQ_VERY_HIGH
PA7.Mode=Full_Duplex_Master
PA7.Signal=SPI1_MOSI
PA8.GPIO_Label=MAX30003_CLK
PA8.Mode=Clock-out-1
PA8.Signal=RCC_MCO_1
PA9.GPIO_Speed=GPIO_SPEED_FREQ_VERY_HIGH
PA9.Mode=Asynchronous
PA9.Signal=USART1_TX
PB0.GPIO_Speed=GPIO_SPEED_FREQ_VERY_HIGH
PB0.Mode=RGB888
PB0.Signal=LTDC_R3
PB1.GPIO_Speed=GPIO_SPEED_FREQ_VERY_HIGH
PB1.Mode=RGB888
PB1.Signal=LTDC_R6
PB10.GPIO_Speed=GPIO_SPEED_FREQ_VERY_HIGH
PB10.Mode=RGB888
PB10.Signal=LTDC_G4
PB11.GPIO_Speed=GPIO_SPEED_FREQ_VERY_HIGH
PB11.Mode=I2C
PB11.Signal=I2C2_SDA
PB12.GPIO_Label=SDCARD_PLG
PB12.GPIO_PuPd=GPIO_PULLUP
PB12.Signal=GPIO_Input
PB13.GPIO_Label=LCD_PWR_EN
PB13.GPIO_PuPd=GPIO_PULLUP
PB13.Signal=GPIO_Output
PB14.GPIO_Speed=GPIO_SPEED_FREQ_VERY_HIGH
PB14.Signal=S_TIM12_CH1
PB15.GPIO_Label=LCD_BL_EN
PB15.GPIO_PuPd=GPIO_PULLUP
PB15.Signal=GPIO_Output
PB3\ (JTDO/TRACESWO).Mode=Trace_Asynchronous_SW
PB3\ (JTDO/TRACESWO).Signal=DEBUG_JTDO-SWO
PB4\ (NJTRST).GPIO_PuPd=GPIO_PULLUP
PB4\ (NJTRST).GPIO_Speed=GPIO_SPEED_FREQ_VERY_HIGH
PB4\ (NJTRST).Mode=Full_Duplex_Master
PB4\ (NJTRST).Signal=SPI1_MISO
PB5.GPIO_Label=MAXM86161_LEFT_INT
PB5.GPIO_ModeDefaultEXTI=GPIO_MODE_IT_FALLING
PB5.GPIO_PuPd=GPIO_PULLUP
PB5.Signal=GPXTI5
PB6.GPIO_Speed=GPIO_SPEED_FREQ_VERY_HIGH
PB6.Mode=I2C
PB6.Signal=I2C1_SCL
PB7.GPIO_Speed=GPIO_SPEED_FREQ_VERY_HIGH
PB7.Mode=I2C
PB7.Signal=I2C1_SDA
PB8.GPIO_Speed=GPIO_SPEED_FREQ_VERY_HIGH
PB8.Mode=RGB888
PB8.Signal=LTDC_B6
PB9.GPIO_Speed=GPIO_SPEED_FREQ_VERY_HIGH
PB9.Mode=RGB888
PB9.Signal=LTDC_B7
PC0.Signal=ADCx_INP10
PC10.Mode=SD_4_bits_Wide_bus
PC10.Signal=SDMMC1_D2
PC11.Mode=SD_4_bits_Wide_bus
PC11.Signal=SDMMC1_D3
PC12.Mode=SD_4_bits_Wide_bus
PC12.Signal=SDMMC1_CK
PC13.GPIO_Label=SPI1_CS2
PC13.GPIO_PuPd=GPIO_PULLUP
PC13.PinState=GPIO_PIN_SET
PC13.Signal=GPIO_Output
PC14-OSC32_IN\ (OSC32_IN).Mode=LSE-External-Oscillator
PC14-OSC32_IN\ (OSC32_IN).Signal=RCC_OSC32_IN
PC15-OSC32_OUT\ (OSC32_OUT).Mode=LSE-External-Oscillator
PC15-OSC32_OUT\ (OSC32_OUT).Signal=RCC_OSC32_OUT
PC4.Signal=ADCx_INP4
PC6.GPIO_Speed=GPIO_SPEED_FREQ_VERY_HIGH
PC6.Mode=Asynchronous
PC6.Signal=USART6_TX
PC7.GPIO_Speed=GPIO_SPEED_FREQ_VERY_HIGH
PC7.Mode=RGB888
PC7.Signal=LTDC_G6
PC8.Mode=SD_4_bits_Wide_bus
PC8.Signal=SDMMC1_D0
PC9.Mode=SD_4_bits_Wide_bus
PC9.Signal=SDMMC1_D1
PD0.Signal=FMC_D2_DA2
PD1.Signal=FMC_D3_DA3
PD10.Signal=FMC_D15_DA15
PD11.GPIO_Label=TOUCH_PWR_EN
PD11.GPIO_PuPd=GPIO_PULLUP
PD11.GPIO_Speed=GPIO_SPEED_FREQ_VERY_HIGH
PD11.PinState=GPIO_PIN_SET
PD11.Signal=GPIO_Output
PD12.GPIO_Speed=GPIO_SPEED_FREQ_VERY_HIGH
PD12.Mode=I2C
PD12.Signal=I2C4_SCL
PD13.GPIO_Speed=GPIO_SPEED_FREQ_VERY_HIGH
PD13.Mode=I2C
PD13.Signal=I2C4_SDA
PD14.Signal=FMC_D0_DA0
PD15.Signal=FMC_D1_DA1
PD2.Mode=SD_4_bits_Wide_bus
PD2.Signal=SDMMC1_CMD
PD4.GPIO_Label=MAXM86161_RIGHT_INT
PD4.GPIO_ModeDefaultEXTI=GPIO_MODE_IT_FALLING
PD4.GPIO_PuPd=GPIO_PULLUP
PD4.Signal=GPXTI4
PD5.GPIO_Label=MAX30003_PWR_EN
PD5.Signal=GPIO_Output
PD6.GPIO_Speed=GPIO_SPEED_FREQ_VERY_HIGH
PD6.Mode=RGB888
PD6.Signal=LTDC_B2
PD7.GPIO_Label=OLIMEX_PWR_EN
PD7.GPIO_Speed=GPIO_SPEED_FREQ_VERY_HIGH
PD7.Signal=GPIO_Output
PD8.Signal=FMC_D13_DA13
PD9.Signal=FMC_D14_DA14
PE0.Signal=FMC_NBL0
PE1.Signal=FMC_NBL1
PE10.Signal=FMC_D7_DA7
PE11.Signal=FMC_D8_DA8
PE12.Signal=FMC_D9_DA9
PE13.Signal=FMC_D10_DA10
PE14.Signal=FMC_D11_DA11
PE15.Signal=FMC_D12_DA12
PE4.GPIO_Speed=GPIO_SPEED_FREQ_VERY_HIGH
PE4.Mode=RGB888
PE4.Signal=LTDC_B0
PE5.GPIO_Speed=GPIO_SPEED_FREQ_VERY_HIGH
PE5.Mode=RGB888
PE5.Signal=LTDC_G0
PE6.GPIO_Speed=GPIO_SPEED_FREQ_VERY_HIGH
PE6.Mode=RGB888
PE6.Signal=LTDC_G1
PE7.Signal=FMC_D4_DA4
PE8.Signal=FMC_D5_DA5
PE9.Signal=FMC_D6_DA6
PF0.Signal=FMC_A0
PF1.Signal=FMC_A1
PF10.GPIO_Speed=GPIO_SPEED_FREQ_VERY_HIGH
PF10.Mode=RGB888
PF10.Signal=LTDC_DE
PF11.Signal=FMC_SDNRAS
PF12.Signal=FMC_A6
PF13.Signal=FMC_A7
PF14.Signal=FMC_A8
PF15.Signal=FMC_A9
PF2.Signal=FMC_A2
PF3.Signal=FMC_A3
PF4.Signal=FMC_A4
PF5.Signal=FMC_A5
PF6.GPIO_Label=MAX30003_CS
PF6.GPIO_PuPd=GPIO_PULLUP
PF6.GPIO_Speed=GPIO_SPEED_FREQ_VERY_HIGH
PF6.PinState=GPIO_PIN_SET
PF6.Signal=GPIO_Output
PF7.GPIO_PuPd=GPIO_PULLUP
PF7.GPIO_Speed=GPIO_SPEED_FREQ_VERY_HIGH
PF7.Mode=Full_Duplex_Master
PF7.Signal=SPI5_SCK
PF8.GPIO_PuPd=GPIO_PULLUP
PF8.GPIO_Speed=GPIO_SPEED_FREQ_VERY_HIGH
PF8.Mode=Full_Duplex_Master
PF8.Signal=SPI5_MISO
PF9.GPIO_PuPd=GPIO_PULLUP
PF9.GPIO_Speed=GPIO_SPEED_FREQ_VERY_HIGH
PF9.Mode=Full_Duplex_Master
PF9.Signal=SPI5_MOSI
PG0.Signal=FMC_A10
PG1.Signal=FMC_A11
PG10.GPIO_Label=LCD_STBY
PG10.GPIO_PuPd=GPIO_PULLUP
PG10.GPIO_Speed=GPIO_SPEED_FREQ_VERY_HIGH
PG10.PinState=GPIO_PIN_SET
PG10.Signal=GPIO_Output
PG11.GPIO_Speed=GPIO_SPEED_FREQ_VERY_HIGH
PG11.Mode=RGB888
PG11.Signal=LTDC_B3
PG12.GPIO_Speed=GPIO_SPEED_FREQ_VERY_HIGH
PG12.Mode=RGB888
PG12.Signal=LTDC_B1
PG13.GPIO_Label=LCD_RESET
PG13.GPIO_PuPd=GPIO_PULLUP
PG13.GPIO_Speed=GPIO_SPEED_FREQ_VERY_HIGH
PG13.PinState=GPIO_PIN_SET
PG13.Signal=GPIO_Output
PG15.Signal=FMC_SDNCAS
PG2.GPIO_Label=MAX30003_INT2B
PG2.GPIO_PuPd=GPIO_PULLUP
PG2.Signal=GPXTI2
PG3.GPIO_Label=MAX30003_INTB
PG3.GPIO_PuPd=GPIO_PULLUP
PG3.Signal=GPXTI3
PG4.Signal=FMC_A14_BA0
PG5.Signal=FMC_A15_BA1
PG6.GPIO_Speed=GPIO_SPEED_FREQ_VERY_HIGH
PG6.Mode=RGB888
PG6.Signal=LTDC_R7
PG7.GPIO_Speed=GPIO_SPEED_FREQ_VERY_HIGH
PG7.Mode=RGB888
PG7.Signal=LTDC_CLK
PG8.Signal=FMC_SDCLK
PG9.GPIO_Speed=GPIO_SPEED_FREQ_VERY_HIGH
PG9.Mode=Asynchronous
PG9.Signal=USART6_RX
PH0-OSC_IN\ (PH0).Mode=HSE-External-Oscillator
PH0-OSC_IN\ (PH0).Signal=RCC_OSC_IN
PH1-OSC_OUT\ (PH1).Mode=HSE-External-Oscillator
PH1-OSC_OUT\ (PH1).Signal=RCC_OSC_OUT
PH10.GPIO_Speed=GPIO_SPEED_FREQ_VERY_HIGH
PH10.Mode=RGB888
PH10.Signal=LTDC_R4
PH11.GPIO_Speed=GPIO_SPEED_FREQ_VERY_HIGH
PH11.Mode=RGB888
PH11.Signal=LTDC_R5
PH12.GPIO_Label=LCD_3V3_EN
PH12.GPIO_PuPd=GPIO_PULLUP
PH12.GPIO_Speed=GPIO_SPEED_FREQ_VERY_HIGH
PH12.PinState=GPIO_PIN_SET
PH12.Signal=GPIO_Output
PH13.GPIO_Label=MAXM86161_RIGHT_EN
PH13.GPIO_PuPd=GPIO_NOPULL
PH13.GPIO_Speed=GPIO_SPEED_FREQ_VERY_HIGH
PH13.PinState=GPIO_PIN_SET
PH13.Signal=GPIO_Output
PH14.GPIO_Speed=GPIO_SPEED_FREQ_VERY_HIGH
PH14.Mode=RGB888
PH14.Signal=LTDC_G3
PH15.GPIO_Label=MAXM86161_LEFT_EN
PH15.GPIO_Speed=GPIO_SPEED_FREQ_VERY_HIGH
PH15.PinState=GPIO_PIN_SET
PH15.Signal=GPIO_Output
PH2.GPIO_Speed=GPIO_SPEED_FREQ_VERY_HIGH
PH2.Mode=RGB888
PH2.Signal=LTDC_R0
PH3.GPIO_Speed=GPIO_SPEED_FREQ_VERY_HIGH
PH3.Mode=RGB888
PH3.Signal=LTDC_R1
PH4.GPIO_Speed=GPIO_SPEED_FREQ_VERY_HIGH
PH4.Mode=I2C
PH4.Signal=I2C2_SCL
PH5.Signal=FMC_SDNWE
PH6.Mode=SdramChipSelect2_1
PH6.Signal=FMC_SDNE1
PH7.Mode=SdramChipSelect2_1
PH7.Signal=FMC_SDCKE1
PH8.GPIO_Speed=GPIO_SPEED_FREQ_VERY_HIGH
PH8.Mode=RGB888
PH8.Signal=LTDC_R2
PH9.GPIO_Label=TOUCH_BUSY
PH9.GPIO_PuPd=GPIO_NOPULL
PH9.Signal=GPIO_Input
PI0.GPIO_Speed=GPIO_SPEED_FREQ_VERY_HIGH
PI0.Mode=RGB888
PI0.Signal=LTDC_G5
PI1.GPIO_Label=TOUCH_PIRQ
PI1.GPIO_ModeDefaultEXTI=GPIO_MODE_IT_FALLING
PI1.GPIO_PuPd=GPIO_PULLUP
PI1.Signal=GPXTI1
PI10.GPIO_Speed=GPIO_SPEED_FREQ_VERY_HIGH
PI10.Mode=RGB888
PI10.Signal=LTDC_HSYNC
PI2.GPIO_Speed=GPIO_SPEED_FREQ_VERY_HIGH
PI2.Mode=RGB888
PI2.Signal=LTDC_G7
PI3.Signal=GPIO_Output
PI4.GPIO_Speed=GPIO_SPEED_FREQ_VERY_HIGH
PI4.Mode=RGB888
PI4.Signal=LTDC_B4
PI5.GPIO_Speed=GPIO_SPEED_FREQ_VERY_HIGH
PI5.Mode=RGB888
PI5.Signal=LTDC_B5
PI6.GPIO_Label=MAX30102_INT
PI6.GPIO_PuPd=GPIO_PULLUP
PI6.Signal=GPXTI6
PI7.Signal=S_TIM8_CH3
PI9.GPIO_Speed=GPIO_SPEED_FREQ_VERY_HIGH
PI9.Mode=RGB888
PI9.Signal=LTDC_VSYNC
ProjectManager.HeapSize=0x3E00
ProjectManager.StackSize=0x3E00
ProjectManager.TargetToolchain=STM32CubeIDE
RCC.ADCFreq_Value=128000000
RCC.APB1Freq_Value=120000000
RCC.APB2Freq_Value=120000000
RCC.APB3Freq_Value=120000000
RCC.APB4Freq_Value=120000000
RCC.CKPERSourceSelection=RCC_CLKPSOURCE_HSE
RCC.CortexFreq_Value=480000000
RCC.D1PPRE=RCC_APB3_DIV2
RCC.D2PPRE1=RCC_APB1_DIV2
RCC.D2PPRE2=RCC_APB2_DIV2
RCC.D3PPRE=RCC_APB4_DIV2
RCC.DIVM1=1
RCC.DIVM2=8
RCC.DIVM3=8
RCC.DIVN1=120
RCC.DIVN2=256
RCC.DIVN3=192
RCC.DIVP3=4
RCC.DIVQ3=4
RCC.DIVR3=10
RCC.HCLKFreq_Value=240000000
RCC.HPRE=RCC_HCLK_DIV2
RCC.HSE_VALUE=8000000
RCC.PLL1_VCI_Range-AdvancedSettings=RCC_PLL1VCIRANGE_0
RCC.PLL2FRACN=0
RCC.PLL3FRACN=0
RCC.PLLFRACN=0
RCC.PLLSourceVirtual=RCC_PLLSOURCE_HSE
RCC.RCC_MCO1Source=RCC_MCO1SOURCE_LSE
RCC.RTCClockSelection=RCC_RTCCLKSOURCE_LSE
RCC.SPI123CLockSelection=RCC_SPI123CLKSOURCE_PLL2
RCC.SYSCLKFreq_VALUE=480000000
RCC.SYSCLKSource=RCC_SYSCLKSOURCE_PLLCLK
RCC.Spi45ClockSelection=RCC_SPI45CLKSOURCE_PLL2
RCC.USBCLockSelection=RCC_USBCLKSOURCE_PLL3
RCC.USBFreq_Value=48000000
SDMMC1.ClockDiv=20
SH.ADCx_INP10.0=ADC1_INP10
SH.ADCx_INP4.0=ADC1_INP4,IN4-Single-Ended
SH.FMC_A0.0=FMC_A0,12b-sda1
SH.FMC_A1.0=FMC_A1,12b-sda1
SH.FMC_A10.0=FMC_A10,12b-sda1
SH.FMC_A11.0=FMC_A11,12b-sda1
SH.FMC_A14_BA0.0=FMC_BA0,FourSdramBanks1
SH.FMC_A15_BA1.0=FMC_BA1,FourSdramBanks1
SH.FMC_A2.0=FMC_A2,12b-sda1
SH.FMC_A3.0=FMC_A3,12b-sda1
SH.FMC_A4.0=FMC_A4,12b-sda1
SH.FMC_A5.0=FMC_A5,12b-sda1
SH.FMC_A6.0=FMC_A6,12b-sda1
SH.FMC_A7.0=FMC_A7,12b-sda1
SH.FMC_A8.0=FMC_A8,12b-sda1
SH.FMC_A9.0=FMC_A9,12b-sda1
SH.FMC_D0_DA0.0=FMC_D0,sd-16b-d1
SH.FMC_D10_DA10.0=FMC_D10,sd-16b-d1
SH.FMC_D11_DA11.0=FMC_D11,sd-16b-d1
SH.FMC_D12_DA12.0=FMC_D12,sd-16b-d1
SH.FMC_D13_DA13.0=FMC_D13,sd-16b-d1
SH.FMC_D14_DA14.0=FMC_D14,sd-16b-d1
SH.FMC_D15_DA15.0=FMC_D15,sd-16b-d1
SH.FMC_D1_DA1.0=FMC_D1,sd-16b-d1
SH.FMC_D2_DA2.0=FMC_D2,sd-16b-d1
SH.FMC_D3_DA3.0=FMC_D3,sd-16b-d1
SH.FMC_D4_DA4.0=FMC_D4,sd-16b-d1
SH.FMC_D5_DA5.0=FMC_D5,sd-16b-d1
SH.FMC_D6_DA6.0=FMC_D6,sd-16b-d1
SH.FMC_D7_DA7.0=FMC_D7,sd-16b-d1
SH.FMC_D8_DA8.0=FMC_D8,sd-16b-d1
SH.FMC_D9_DA9.0=FMC_D9,sd-16b-d1
SH.FMC_NBL0.0=FMC_NBL0
SH.FMC_NBL1.0=FMC_NBL1
SH.FMC_SDCLK.0=FMC_SDCLK,12b-sda1
SH.FMC_SDNCAS.0=FMC_SDNCAS,12b-sda1
SH.FMC_SDNRAS.0=FMC_SDNRAS,12b-sda1
SH.FMC_SDNWE.0=FMC_SDNWE,12b-sda1
SH.S_TIM12_CH1.0=TIM12_CH1,PWM Generation1 CH1
SH.S_TIM2_CH1.0=TIM2_CH1,Output Compare1 CH1
SH.S_TIM8_CH3.0=TIM8_CH3,Output Compare3 CH3
SPI1.BaudRatePrescaler=SPI_BAUDRATEPRESCALER_256
SPI1.CalculateBaudRate=500.0 KBits/s
SPI1.DataSize=SPI_DATASIZE_8BIT
SPI1.Direction=SPI_DIRECTION_2LINES
SPI1.Mode=SPI_MODE_MASTER
SPI1.VirtualType=VM_MASTER
SPI5.BaudRatePrescaler=SPI_BAUDRATEPRESCALER_128
SPI5.CalculateBaudRate=1000.0 KBits/s
SPI5.DataSize=SPI_DATASIZE_8BIT
SPI5.Direction=SPI_DIRECTION_2LINES
SPI5.Mode=SPI_MODE_MASTER
SPI5.VirtualType=VM_MASTER
STMicroelectronics.X-CUBE-TOUCHGFX.4.15.0.ApplicationCcGraphicsJjApplication=TouchGFXOoGenerator
STMicroelectronics.X-CUBE-TOUCHGFX.4.15.0.tgfx_address1=0xD0000000
STMicroelectronics.X-CUBE-TOUCHGFX.4.15.0.tgfx_address2=0xD0119600
STMicroelectronics.X-CUBE-TOUCHGFX.4.15.0.tgfx_buffering_strategy=Double
STMicroelectronics.X-CUBE-TOUCHGFX.4.15.0.tgfx_display_interface=disp_ltdc
STMicroelectronics.X-CUBE-TOUCHGFX.4.15.0.tgfx_hardware_accelerator=dma_2d
STMicroelectronics.X-CUBE-TOUCHGFX.4.15.0.tgfx_location=By Address
STMicroelectronics.X-CUBE-TOUCHGFX.4.15.0.tgfx_vsync=vsync_ltdc
TIM12.Channel-PWM\ Generation1\ CH1=TIM_CHANNEL_1
TIM12.ClockDivision=TIM_CLOCKDIVISION_DIV4
TIM12.OCPolarity_1=TIM_OCPOLARITY_LOW
TIM12.Period=999
TIM12.Prescaler=59
TIM12.Pulse-PWM\ Generation1\ CH1=499
TIM13.Channel=TIM_CHANNEL_1
TIM13.ClockDivision=TIM_CLOCKDIVISION_DIV4
TIM13.Period=999
TIM13.Prescaler=59
TIM2.Channel-Output\ Compare1\ CH1=TIM_CHANNEL_1
TIM2.OCPolarity_1=TIM_OCPOLARITY_LOW
TIM2.Period=0
TIM2.Prescaler=119
TIM3.Channel-Output\ Compare1\ No\ Output=TIM_CHANNEL_1
TIM3.ClockDivision=TIM_CLOCKDIVISION_DIV4
TIM3.Period=4
TIM3.Prescaler=14999
TIM3.TIM_MasterOutputTrigger=TIM_TRGO_UPDATE
TIM7.Period=99
TIM7.Prescaler=44999
TIM7.TIM_MasterOutputTrigger=TIM_TRGO_UPDATE
TIM8.Channel-Output\ Compare3\ CH3=TIM_CHANNEL_3
TIM8.OCPolarity_3=TIM_OCPOLARITY_LOW
TIM8.Period=0
TIM8.Prescaler=119
USART1.VirtualMode-Asynchronous=VM_ASYNC
USART2.VirtualMode-Asynchronous=VM_ASYNC
USART6.VirtualMode-Asynchronous=VM_ASYNC
USB_DEVICE.CLASS_NAME_FS=MSC
USB_DEVICE.MANUFACTURER_STRING-MSC_FS=Hardway Industries
USB_DEVICE.PRODUCT_STRING_MSC_FS=SS3RDH7
USB_DEVICE.VirtualMode-MSC_FS=Msc
USB_DEVICE.VirtualModeFS=Msc_FS
USB_OTG_FS.VirtualMode=Device_Only
USB_OTG_FS.dma_enable=ENABLE
VP_CRC_VS_CRC.Mode=CRC_Activate
VP_DMA2D_VS_DMA2D.Mode=DMA2D_Activate
VP_FATFS_VS_SDIO.Mode=SDIO
VP_FREERTOS_VS_CMSIS_V2.Mode=CMSIS_V2
VP_JPEG_VS_JPEG.Mode=JPEG_Activate
VP_LIBJPEG_VS_JPEGLIB.Mode=Enabled
VP_RTC_VS_RTC_Activate.Mode=RTC_Enabled
VP_RTC_VS_RTC_Calendar.Mode=RTC_Calendar
VP_STMicroelectronics.X-CUBE-TOUCHGFX_VS_GraphicsJjApplication_4.15.0.Mode=GraphicsJjApplication
VP_SYS_VS_tim6.Mode=TIM6
VP_TIM13_VS_ClockSourceINT.Mode=Enable_Timer
VP_TIM13_VS_no_output1.Mode=Output Compare1 No Output
VP_TIM3_VS_ClockSourceINT.Mode=Internal
VP_TIM3_VS_no_output1.Mode=Output Compare1 No Output
VP_TIM7_VS_ClockSourceINT.Mode=Enable_Timer
VP_USB_DEVICE_VS_USB_DEVICE_MSC_FS.Mode=MSC_FS
board=custom

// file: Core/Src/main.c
/* USER CODE BEGIN Header */
/**
  ******************************************************************************
  * @file           : main.c
  * @brief          : Main program body
  ******************************************************************************
  * @attention
  *
  * <h2><center>&copy; Copyright (c) 2020 STMicroelectronics.
  * All rights reserved.</center></h2>
  *
  * This software component is licensed by ST under Ultimate Liberty license
  * SLA0044, the "License"; You may not use this file except in compliance with
  * the License. You may obtain a copy of the License at:
  *                             www.st.com/SLA0044
  *
  ******************************************************************************
  */
/* USER CODE END Header */
#include "main.h"
#include "cmsis_os.h"
#include "adc.h"
#include "bdma.h"
#include "crc.h"
#include "dma.h"
#include "dma2d.h"
#include "fatfs.h"
#include "i2c.h"
#include "jpeg.h"
#include "libjpeg.h"
#include "ltdc.h"
#include "rtc.h"
#include "sdmmc.h"
#include "spi.h"
#include "tim.h"
#include "usart.h"
#include "usb_device.h"
#include "gpio.h"
#include "fmc.h"
#include "app_touchgfx.h"

/* USER CODE BEGIN Includes */
#include <stdio.h>
#include "display/display.h"
#include "devices/touch/XPT2046.h"
#include "devices/touch/XPT2046LL.h"
#include "devices/ecg/MAX30003LL.h"
#include "devices/ppg/MAX30102LL.h"
#include "devices/ppg/MAX86161LL.h"
/* USER CODE END Includes */

void SystemClock_Config(void);
void MX_FREERTOS_Init(void);
/* USER CODE BEGIN PFP */
TouchEvent_t event;
extern osThreadId touchEventTaskHandle;
/* USER CODE END PFP */

/* USER CODE BEGIN 0 */
void xpt2046TouchEventCallback(TouchEvent_t* e) {
    event.xPosition = e->xPosition;
    event.yPosition = e->yPosition;
    event.batteryVoltage = e->batteryVoltage;
    event.auxValue = e->auxValue;
    event.temperature = e->temperature;
    event.z1Position = e->z1Position;
    event.z2Position = e->z2Position;
    osThreadResume(touchEventTaskHandle);
}

void HAL_SPI_TxRxCpltCallback(SPI_HandleTypeDef *hspi) {
	if(hspi->Instance == SPI1) {
		xpt2046LowLevelSpiTxRxHandler(hspi);
	} else if(hspi->Instance == SPI5) {
		max30003LowLevelSpiTxRxHandler(hspi);
	}
}

int _write(int file, char *ptr, int len) {
	for(int i = 0; i < len; i++) {
		ITM_SendChar(ptr[i]);
	}
	return len;
}
/* USER CODE END 0 */

int main(void)
{

  /* Enable I-Cache---------------------------------------------------------*/
  SCB_EnableICache();

  /* Enable D-Cache---------------------------------------------------------*/
  //SCB_EnableDCache();

  /* MCU Configuration--------------------------------------------------------*/

  /* Reset of all peripherals, Initializes the Flash interface and the Systick. */
  HAL_Init();

  /* Configure the system clock */
  SystemClock_Config();

  /* Initialize all configured peripherals */
  MX_GPIO_Init();
  MX_BDMA_Init();
  MX_DMA_Init();
  MX_DMA2D_Init();
  MX_FMC_Init();
  SDRAM_InitSequence();
  MX_I2C1_Init();
  MX_I2C2_Init();
  MX_LTDC_Init();
  MX_SDMMC1_SD_Init();
  MX_SPI1_Init();
  MX_SPI5_Init();
  MX_UART4_Init();
  MX_USART1_UART_Init();
  MX_USART2_UART_Init();
  MX_USART6_UART_Init();
  MX_FATFS_Init();
  MX_LIBJPEG_Init();
  MX_JPEG_Init();
  MX_ADC1_Init();
  MX_CRC_Init();
  MX_RTC_Init();
  MX_TIM3_Init();
  MX_TIM7_Init();
  MX_TIM12_Init();
  MX_TIM13_Init();
  MX_I2C4_Init();
  MX_TIM2_Init();
  MX_TIM8_Init();
  MX_TouchGFX_Init();
  /* USER CODE BEGIN 2 */
  HAL_Delay(100);
  HAL_GPIO_WritePin(GPIOD, MAX30003_PWR_EN_Pin|OLIMEX_PWR_EN_Pin, GPIO_PIN_SET);
  HAL_TIM_Base_Start(&htim3);
  HAL_TIM_Base_Start_IT(&htim7);
  HAL_TIM_PWM_Start(&htim12, TIM_CHANNEL_1);
  HAL_ADC_Start_IT(&hadc1);

  //HAL_TIM_Base_Start(&htim2);
  //HAL_TIM_Base_Start(&htim8);

  HAL_TIM_OC_Start(&htim2, TIM_CHANNEL_1);
  HAL_TIM_OC_Start(&htim8, TIM_CHANNEL_3);
  /* USER CODE END 2 */

  /* Init scheduler */
  osKernelInitialize();  /* Call init function for freertos objects (in freertos.c) */
  MX_FREERTOS_Init();
  /* Start scheduler */
  osKernelStart();

  /* We should never get here as control is now taken by the scheduler */
  /* Infinite loop */
  while (1)
  {

  }
}

void SystemClock_Config(void)
{
  RCC_OscInitTypeDef RCC_OscInitStruct = {0};
  RCC_ClkInitTypeDef RCC_ClkInitStruct = {0};
  RCC_PeriphCLKInitTypeDef PeriphClkInitStruct = {0};

  /** Supply configuration update enable
  */
  HAL_PWREx_ConfigSupply(PWR_LDO_SUPPLY);
  /** Configure the main internal regulator output voltage
  */
  __HAL_PWR_VOLTAGESCALING_CONFIG(PWR_REGULATOR_VOLTAGE_SCALE0);

  while(!__HAL_PWR_GET_FLAG(PWR_FLAG_VOSRDY)) {}
  /** Configure LSE Drive Capability
  */
  HAL_PWR_EnableBkUpAccess();
  //__HAL_RCC_LSEDRIVE_CONFIG(RCC_LSEDRIVE_LOW);
#if RTC_CLOCK_SOURCE == RTC_CLOCK_SOURCE_LSE
  //__HAL_RCC_LSEDRIVE_CONFIG(RCC_LSEDRIVE_LOW);
  //__HAL_RCC_LSEDRIVE_CONFIG(RCC_LSEDRIVE_MEDIUMLOW);
  //__HAL_RCC_LSEDRIVE_CONFIG(RCC_LSEDRIVE_MEDIUMHIGH);
  __HAL_RCC_LSEDRIVE_CONFIG(RCC_LSEDRIVE_HIGH);
#endif
  /** Macro to configure the PLL clock source
  */
  __HAL_RCC_PLL_PLLSOURCE_CONFIG(RCC_PLLSOURCE_HSE);
  /** Initializes the RCC Oscillators according to the specified parameters
  * in the RCC_OscInitTypeDef structure.
  */
  RCC_OscInitStruct.OscillatorType = RCC_OSCILLATORTYPE_HSE;
#if RTC_CLOCK_SOURCE == RTC_CLOCK_SOURCE_LSE
  RCC_OscInitStruct.OscillatorType |= RCC_OSCILLATORTYPE_LSE;//|RCC_OSCILLATORTYPE_LSE;
  RCC_OscInitStruct.LSEState = RCC_LSE_ON;
#else
  RCC_OscInitStruct.OscillatorType |= RCC_OSCILLATORTYPE_LSI;
#endif
  RCC_OscInitStruct.HSEState = RCC_HSE_ON;
  RCC_OscInitStruct.LSEState = RCC_LSI_ON;
  RCC_OscInitStruct.PLL.PLLState = RCC_PLL_ON;
  RCC_OscInitStruct.PLL.PLLSource = RCC_PLLSOURCE_HSE;
  RCC_OscInitStruct.PLL.PLLM = 1;
  RCC_OscInitStruct.PLL.PLLN = 120;
  RCC_OscInitStruct.PLL.PLLP = 2;
  RCC_OscInitStruct.PLL.PLLQ = 2;
  RCC_OscInitStruct.PLL.PLLR = 2;
  RCC_OscInitStruct.PLL.PLLRGE = RCC_PLL1VCIRANGE_3;
  RCC_OscInitStruct.PLL.PLLVCOSEL = RCC_PLL1VCOWIDE;
  RCC_OscInitStruct.PLL.PLLFRACN = 0;
  if (HAL_RCC_OscConfig(&RCC_OscInitStruct) != HAL_OK)
  {
    Error_Handler();
  }
  /** Initializes the CPU, AHB and APB buses clocks
  */
  RCC_ClkInitStruct.ClockType = RCC_CLOCKTYPE_HCLK|RCC_CLOCKTYPE_SYSCLK
                              |RCC_CLOCKTYPE_PCLK1|RCC_CLOCKTYPE_PCLK2
                              |RCC_CLOCKTYPE_D3PCLK1|RCC_CLOCKTYPE_D1PCLK1;
  RCC_ClkInitStruct.SYSCLKSource = RCC_SYSCLKSOURCE_PLLCLK;
  RCC_ClkInitStruct.SYSCLKDivider = RCC_SYSCLK_DIV1;
  RCC_ClkInitStruct.AHBCLKDivider = RCC_HCLK_DIV2;
  RCC_ClkInitStruct.APB3CLKDivider = RCC_APB3_DIV2;
  RCC_ClkInitStruct.APB1CLKDivider = RCC_APB1_DIV2;
  RCC_ClkInitStruct.APB2CLKDivider = RCC_APB2_DIV2;
  RCC_ClkInitStruct.APB4CLKDivider = RCC_APB4_DIV2;

  if (HAL_RCC_ClockConfig(&RCC_ClkInitStruct, FLASH_LATENCY_4) != HAL_OK)
  {
    Error_Handler();
  }
  PeriphClkInitStruct.PeriphClockSelection = RCC_PERIPHCLK_RTC|RCC_PERIPHCLK_LTDC
                              |RCC_PERIPHCLK_USART2|RCC_PERIPHCLK_UART4
                              |RCC_PERIPHCLK_USART6|RCC_PERIPHCLK_USART1
                              |RCC_PERIPHCLK_SPI5|RCC_PERIPHCLK_SPI1
                              |RCC_PERIPHCLK_SDMMC|RCC_PERIPHCLK_I2C2
                              |RCC_PERIPHCLK_ADC|RCC_PERIPHCLK_I2C1
                              |RCC_PERIPHCLK_I2C4|RCC_PERIPHCLK_USB
                              |RCC_PERIPHCLK_FMC;
  PeriphClkInitStruct.PLL2.PLL2M = 8;
  PeriphClkInitStruct.PLL2.PLL2N = 256;
  PeriphClkInitStruct.PLL2.PLL2P = 2;
  PeriphClkInitStruct.PLL2.PLL2Q = 2;
  PeriphClkInitStruct.PLL2.PLL2R = 2;
  PeriphClkInitStruct.PLL2.PLL2RGE = RCC_PLL2VCIRANGE_0;
  PeriphClkInitStruct.PLL2.PLL2VCOSEL = RCC_PLL2VCOWIDE;
  PeriphClkInitStruct.PLL2.PLL2FRACN = 0;
  PeriphClkInitStruct.PLL3.PLL3M = 8;
  PeriphClkInitStruct.PLL3.PLL3N = 192;
  PeriphClkInitStruct.PLL3.PLL3P = 4;
  PeriphClkInitStruct.PLL3.PLL3Q = 4;
  PeriphClkInitStruct.PLL3.PLL3R = 9;
  PeriphClkInitStruct.PLL3.PLL3RGE = RCC_PLL3VCIRANGE_0;
  PeriphClkInitStruct.PLL3.PLL3VCOSEL = RCC_PLL3VCOWIDE;
  PeriphClkInitStruct.PLL3.PLL3FRACN = 0;
  PeriphClkInitStruct.FmcClockSelection = RCC_FMCCLKSOURCE_D1HCLK;
  PeriphClkInitStruct.SdmmcClockSelection = RCC_SDMMCCLKSOURCE_PLL;
  PeriphClkInitStruct.Spi123ClockSelection = RCC_SPI123CLKSOURCE_PLL2;
  PeriphClkInitStruct.Spi45ClockSelection = RCC_SPI45CLKSOURCE_PLL2;
  PeriphClkInitStruct.Usart234578ClockSelection = RCC_USART234578CLKSOURCE_D2PCLK1;
  PeriphClkInitStruct.Usart16ClockSelection = RCC_USART16CLKSOURCE_D2PCLK2;
  PeriphClkInitStruct.I2c123ClockSelection = RCC_I2C123CLKSOURCE_D2PCLK1;
  PeriphClkInitStruct.UsbClockSelection = RCC_USBCLKSOURCE_PLL3;
  PeriphClkInitStruct.I2c4ClockSelection = RCC_I2C4CLKSOURCE_D3PCLK1;
  PeriphClkInitStruct.AdcClockSelection = RCC_ADCCLKSOURCE_PLL2;
#if RTC_CLOCK_SOURCE == RTC_CLOCK_SOURCE_LSE
  PeriphClkInitStruct.RTCClockSelection = RCC_RTCCLKSOURCE_LSE;//RCC_RTCCLKSOURCE_LSE
#else
  PeriphClkInitStruct.RTCClockSelection = RCC_RTCCLKSOURCE_LSI;
#endif
  if (HAL_RCCEx_PeriphCLKConfig(&PeriphClkInitStruct) != HAL_OK)
  {
    Error_Handler();
  }
  HAL_RCC_MCOConfig(RCC_MCO1, RCC_MCO1SOURCE_LSE, RCC_MCODIV_1);
  /** Enable USB Voltage detector
  */
  HAL_PWREx_EnableUSBVoltageDetector();
}

 /**
  * @brief  Period elapsed callback in non blocking mode
  * @note   This function is called  when TIM6 interrupt took place, inside
  * HAL_TIM_IRQHandler(). It makes a direct call to HAL_IncTick() to increment
  * a global variable "uwTick" used as application time base.
  * @param  htim : TIM handle
  * @retval None
  */
void HAL_TIM_PeriodElapsedCallback(TIM_HandleTypeDef *htim)
{
  if (htim->Instance == TIM6) {
    HAL_IncTick();
  }
}

void Error_Handler(void)
{
}

/************************ (C) COPYRIGHT STMicroelectronics *****END OF FILE****/

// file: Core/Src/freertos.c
/* USER CODE BEGIN Header */
/**
  ******************************************************************************
  * File Name          : freertos.c
  * Description        : Code for freertos applications
  ******************************************************************************
  * @attention
  *
  * <h2><center>&copy; Copyright (c) 2020 STMicroelectronics.
  * All rights reserved.</center></h2>
  *
  * This software component is licensed by ST under Ultimate Liberty license
  * SLA0044, the "License"; You may not use this file except in compliance with
  * the License. You may obtain a copy of the License at:
  *                             www.st.com/SLA0044
  *
  ******************************************************************************
  */
/* USER CODE END Header */

#include "FreeRTOS.h"
#include "task.h"
#include "main.h"
#include "cmsis_os.h"

/* USER CODE BEGIN Includes */
#include "app_touchgfx.h"
#include "fatfs.h"
#include "semphr.h"
#include "usbd_def.h"
#include <stdio.h>
#include "app_touchgfx.h"
#include "devices/touch/XPT2046.h"
#include "devices/touch/XPT2046LL.h"
#include "devices/ecg/MAX30003LL.h"
#include "devices/ppg/MAX30102LL.h"
#include "devices/ppg/MAX86161LL.h"
#include "fatfs.h"
#include "semphr.h"
#include "usbd_def.h"
#include "utils/file_utils.h"
#include "domain/use_cases/recording_use_case.h"
#include "domain/use_cases/testing_use_case.h"
/* USER CODE END Includes */

/* USER CODE BEGIN PTD */

extern TouchEvent_t event;
extern MAX30003Device_t max30003device;
extern MAX30102Device_t max30102device;
extern MAX86161Device_t max86161RightDevice; // I2C2
extern MAX86161Device_t max86161LeftDevice;	 // I2C1
extern I2C_HandleTypeDef hi2c1;
extern I2C_HandleTypeDef hi2c2;
extern I2C_HandleTypeDef hi2c4;
extern DMA_HandleTypeDef hdma_sdio_rx;
extern DMA_HandleTypeDef hdma_sdio_tx;
extern PCD_HandleTypeDef hpcd_USB_OTG_FS;
extern XPT2046Device_t xpt2046Device;

ECGData_t max30003ECGEvent;
MAX30102PPGData_t max30102PPGEvent;
MAXM86161PPGData_t max86161RightPPGEvent;
MAXM86161PPGData_t max86161LeftPPGEvent;

uint8_t max300032Counter = 0;
uint8_t max30102Counter = 0;
uint8_t max86161RightCounter = 0;
uint8_t max86161LeftCounter = 0;

//__attribute__ ((section(".buffers"), used))
//char wtext[ECG_BUFFER_SIZE * 10 * 3];
/* USER CODE END PTD */

/* USER CODE BEGIN Variables */
QueueHandle_t standartECGQueue = 0;
QueueHandle_t earECGQueue = 0;
QueueHandle_t fingerPPGRedQueue = 0;
QueueHandle_t fingerPPGIRQueue = 0;
QueueHandle_t earPPGLeftGreenQueue = 0;
QueueHandle_t earPPGLeftRedQueue = 0;
QueueHandle_t earPPGLeftIRQueue = 0;
QueueHandle_t earPPGRightGreenQueue = 0;
QueueHandle_t earPPGRightRedQueue = 0;
QueueHandle_t earPPGRightIRQueue = 0;

SemaphoreHandle_t i2c1TxBinarySemaphore;
SemaphoreHandle_t i2c1RxBinarySemaphore;
SemaphoreHandle_t i2c1ErrorBinarySemaphore;
SemaphoreHandle_t i2c2TxBinarySemaphore;
SemaphoreHandle_t i2c2RxBinarySemaphore;
SemaphoreHandle_t i2c2ErrorBinarySemaphore;
SemaphoreHandle_t i2c4TxBinarySemaphore;
SemaphoreHandle_t i2c4RxBinarySemaphore;
SemaphoreHandle_t i2c4ErrorBinarySemaphore;

SemaphoreHandle_t max30102IRQBinarySemaphore;
SemaphoreHandle_t maxm86161LeftIRQBinarySemaphore;
SemaphoreHandle_t maxm86161RightIRQBinarySemaphore;
SemaphoreHandle_t touchIRQBinarySemaphore;
SemaphoreHandle_t max30003IRQBinarySemaphore;

SemaphoreHandle_t usbBinarySemaphore;
SemaphoreHandle_t usbDmaTxBinarySemaphore;
SemaphoreHandle_t usbDmaRxBinarySemaphore;
SemaphoreHandle_t usbReadBinarySemaphore;
SemaphoreHandle_t usbWriteBinarySemaphore;
SemaphoreHandle_t testBinarySemaphore;

SemaphoreHandle_t i2c1MutexSemaphore;
SemaphoreHandle_t i2c2MutexSemaphore;
SemaphoreHandle_t i2c4MutexSemaphore;

SemaphoreHandle_t fsMutexSemaphore;

SemaphoreHandle_t storeEcgBinarySemaphore;

static char debugInfoBuffer[RTOS_DEBUG_BUFFER_SIZE];
static char currentFilename[FILE_UTILS_GENERATED_NAME_LENGTH_BYTES];

/* USER CODE END Variables */
/* Definitions for defaultTask */
osThreadId_t defaultTaskHandle;
const osThreadAttr_t defaultTask_attributes = {
  .name = "defaultTask",
  .priority = (osPriority_t) osPriorityLow,
  .stack_size = 1024 * 8
};
/* Definitions for touchTask */
osThreadId_t touchTaskHandle;
const osThreadAttr_t touchTask_attributes = {
  .name = "touchTask",
  .priority = (osPriority_t) osPriorityNormal,
  .stack_size = 1024 * 4
};
/* Definitions for touchIRQTask */
osThreadId_t touchIRQTaskHandle;
const osThreadAttr_t touchIRQTask_attributes = {
  .name = "touchIRQTask",
  .priority = (osPriority_t) osPriorityNormal,
  .stack_size = 1024 * 4
};
/* Definitions for max30003Task */
osThreadId_t max30003TaskHandle;
const osThreadAttr_t max30003Task_attributes = {
  .name = "max30003Task",
  .priority = (osPriority_t) osPriorityNormal,
  .stack_size = 1024 * 4
};
/* Definitions for max30003IRQTask */
osThreadId_t max30003IRQTaskHandle;
const osThreadAttr_t max30003IRQTask_attributes = {
  .name = "max30003IRQTask",
  .priority = (osPriority_t) osPriorityISR,
  .stack_size = 1024 * 4
};
/* Definitions for max30102Task */
osThreadId_t max30102TaskHandle;
const osThreadAttr_t max30102Task_attributes = {
  .name = "max30102Task",
  .priority = (osPriority_t) osPriorityNormal,
  .stack_size = 1024 * 4
};
/* Definitions for max30102IRQTask */
osThreadId_t max30102IRQTaskHandle;
const osThreadAttr_t max30102IRQTask_attributes = {
  .name = "max30102IRQTask",
  .priority = (osPriority_t) osPriorityISR,
  .stack_size = 1024 * 4
};
/* Definitions for maxm86161RTask */
osThreadId_t maxm86161RTaskHandle;
const osThreadAttr_t maxm86161RTask_attributes = {
  .name = "maxm86161RTask",
  .priority = (osPriority_t) osPriorityNormal,
  .stack_size = 1024 * 4
};
/* Definitions for maxm86161IRTask */
osThreadId_t maxm86161IRTaskHandle;
const osThreadAttr_t maxm86161IRTask_attributes = {
  .name = "maxm86161IRTask",
  .priority = (osPriority_t) osPriorityNormal,
  .stack_size = 1024 * 4
};
/* Definitions for maxm86161LTask */
osThreadId_t maxm86161LTaskHandle;
const osThreadAttr_t maxm86161LTask_attributes = {
  .name = "maxm86161LTask",
  .priority = (osPriority_t) osPriorityNormal,
  .stack_size = 1024 * 4
};
/* Definitions for maxm86161ILTask */
osThreadId_t maxm86161ILTaskHandle;
const osThreadAttr_t maxm86161ILTask_attributes = {
  .name = "maxm86161ILTask",
  .priority = (osPriority_t) osPriorityNormal,
  .stack_size = 1024 * 4
};
/* Definitions for i2c1TxTask */
osThreadId_t i2c1TxTaskHandle;
const osThreadAttr_t i2c1TxTask_attributes = {
  .name = "i2c1TxTask",
  .priority = (osPriority_t) osPriorityISR,
  .stack_size = 1024 * 4
};
/* Definitions for i2c1RxTask */
osThreadId_t i2c1RxTaskHandle;
const osThreadAttr_t i2c1RxTask_attributes = {
  .name = "i2c1RxTask",
  .priority = (osPriority_t) osPriorityISR,
  .stack_size = 1024 * 4
};
/* Definitions for i2c1ErrorTask */
osThreadId_t i2c1ErrorTaskHandle;
const osThreadAttr_t i2c1ErrorTask_attributes = {
  .name = "i2c1ErrorTask",
  .priority = (osPriority_t) osPriorityISR,
  .stack_size = 1024 * 4
};
/* Definitions for i2c2TxTask */
osThreadId_t i2c2TxTaskHandle;
const osThreadAttr_t i2c2TxTask_attributes = {
  .name = "i2c2TxTask",
  .priority = (osPriority_t) osPriorityISR,
  .stack_size = 1024 * 4
};
/* Definitions for i2c2RxTask */
osThreadId_t i2c2RxTaskHandle;
const osThreadAttr_t i2c2RxTask_attributes = {
  .name = "i2c2RxTask",
  .priority = (osPriority_t) osPriorityISR,
  .stack_size = 1024 * 4
};
/* Definitions for i2c2ErrorTask */
osThreadId_t i2c2ErrorTaskHandle;
const osThreadAttr_t i2c2ErrorTask_attributes = {
  .name = "i2c2ErrorTask",
  .priority = (osPriority_t) osPriorityISR,
  .stack_size = 1024 * 4
};
/* Definitions for debugTask */
osThreadId_t debugTaskHandle;
const osThreadAttr_t debugTask_attributes = {
  .name = "debugTask",
  .priority = (osPriority_t) osPriorityNormal,
  .stack_size = 1024 * 4
};
/* Definitions for fatFsTask */
osThreadId_t fatFsTaskHandle;
const osThreadAttr_t fatFsTask_attributes = {
  .name = "fatFsTask",
  .priority = (osPriority_t) osPriorityNormal,
  .stack_size = 1024 * 6
};
/* Definitions for usbTask */
osThreadId_t usbTaskHandle;
const osThreadAttr_t usbTask_attributes = {
  .name = "usbTask",
  .priority = (osPriority_t) osPriorityNormal,
  .stack_size = 1024 * 4
};
/* Definitions for usbDmaTxTask */
osThreadId_t usbDmaTxTaskHandle;
const osThreadAttr_t usbDmaTxTask_attributes = {
  .name = "usbDmaTxTask",
  .priority = (osPriority_t) osPriorityNormal,
  .stack_size = 1024 * 4
};
/* Definitions for usbDmaRxTask */
osThreadId_t usbDmaRxTaskHandle;
const osThreadAttr_t usbDmaRxTask_attributes = {
  .name = "usbDmaRxTask",
  .priority = (osPriority_t) osPriorityNormal,
  .stack_size = 1024 * 4
};
/* Definitions for i2c4TxTask */
osThreadId_t i2c4TxTaskHandle;
const osThreadAttr_t i2c4TxTask_attributes = {
  .name = "i2c4TxTask",
  .priority = (osPriority_t) osPriorityISR,
  .stack_size = 1024 * 4
};
/* Definitions for i2c4RxTask */
osThreadId_t i2c4RxTaskHandle;
const osThreadAttr_t i2c4RxTask_attributes = {
  .name = "i2c4RxTask",
  .priority = (osPriority_t) osPriorityISR,
  .stack_size = 1024 * 4
};
/* Definitions for i2c4ErrorTask */
osThreadId_t i2c4ErrorTaskHandle;
const osThreadAttr_t i2c4ErrorTask_attributes = {
  .name = "i2c4ErrorTask",
  .priority = (osPriority_t) osPriorityISR,
  .stack_size = 1024 * 4
};

osThreadId_t testTaskHandle;
const osThreadAttr_t testTask_attributes = {
  .name = "testTask",
  .priority = (osPriority_t) osPriorityNormal,
  .stack_size = 1024 * 16
};

/* USER CODE BEGIN FunctionPrototypes */
void HAL_I2C_MasterRxCpltCallback(I2C_HandleTypeDef *hi2c) {
	if(hi2c->Instance == I2C1) {
		xSemaphoreGiveFromISR(i2c1RxBinarySemaphore, pdTRUE);
		portYIELD_FROM_ISR(pdTRUE);
	} else if(hi2c->Instance == I2C2) {
		xSemaphoreGiveFromISR(i2c2RxBinarySemaphore, pdTRUE);
		portYIELD_FROM_ISR(pdTRUE);
	} else if(hi2c->Instance == I2C4) {
		xSemaphoreGiveFromISR(i2c4RxBinarySemaphore, pdTRUE);
		portYIELD_FROM_ISR(pdTRUE);
	}
}

void HAL_I2C_MasterTxCpltCallback(I2C_HandleTypeDef *hi2c) {
	if(hi2c->Instance == I2C1) {
		xSemaphoreGiveFromISR(i2c1TxBinarySemaphore, pdTRUE);
		portYIELD_FROM_ISR(pdTRUE);
	} else if(hi2c->Instance == I2C2) {
		xSemaphoreGiveFromISR(i2c2TxBinarySemaphore, pdTRUE);
		portYIELD_FROM_ISR(pdTRUE);
	} else if(hi2c->Instance == I2C4) {
		xSemaphoreGiveFromISR(i2c4TxBinarySemaphore, pdTRUE);
		portYIELD_FROM_ISR(pdTRUE);
	}
}

void HAL_I2C_ErrorCallback(I2C_HandleTypeDef *hi2c) {
	if(hi2c->Instance == I2C1) {
		xSemaphoreGiveFromISR(i2c1ErrorBinarySemaphore, pdTRUE);
		portYIELD_FROM_ISR(pdTRUE);
	} else if(hi2c->Instance == I2C2) {
		xSemaphoreGiveFromISR(i2c2ErrorBinarySemaphore, pdTRUE);
		portYIELD_FROM_ISR(pdTRUE);
	} else if(hi2c->Instance == I2C4) {
		xSemaphoreGiveFromISR(i2c4ErrorBinarySemaphore, pdTRUE);
		portYIELD_FROM_ISR(pdTRUE);
	}
}

void max30003ECGDataHandler(ECGData_t* ecgEvent) {
	max30003ECGEvent.sample = ecgEvent->sample;

	storeSampleECG((uint16_t)max30003ECGEvent.sample);

	if(max300032Counter < GRAPH_DOWNSAMPLING_VALUE) {
		max300032Counter++;
	} else {
		max300032Counter = 0;
		xQueueSendFromISR(standartECGQueue, (void *)&(max30003ECGEvent.sample), (TickType_t)0);
	}
}

void max30003ECGDataCallback(ECGData_t* ecgEvent) {
	max30003ECGDataHandler(ecgEvent);
	max30003ECGDataHandler(ecgEvent);
	max30003ECGDataHandler(ecgEvent);
	max30003ECGDataHandler(ecgEvent);
	max30003ECGDataHandler(ecgEvent);
	//max30003ECGDataHandler(ecgEvent);
	//max30003ECGDataHandler(ecgEvent);
}

void max30102PPGDataCallback(MAX30102PPGData_t* ppgEvent) {
	max30102PPGEvent.redSample = ppgEvent->redSample;
	max30102PPGEvent.irSample = ppgEvent->irSample;

	storeSamplePPGFingerRed(max30102PPGEvent.redSample);
	storeSamplePPGFingerIR(max30102PPGEvent.irSample);

	if(max30102Counter < GRAPH_DOWNSAMPLING_VALUE) {
		max30102Counter++;
	} else {
		max30102Counter = 0;
		xQueueSendFromISR(fingerPPGRedQueue, (void *)&(max30102PPGEvent.redSample), (TickType_t)0);
		xQueueSendFromISR(fingerPPGIRQueue, (void *)&(max30102PPGEvent.irSample), (TickType_t)0);
	}
}

void max86161RightPPGDataHandler(MAXM86161PPGData_t* ppgEvent) {
	max86161RightPPGEvent.redSample = ppgEvent->redSample;
	max86161RightPPGEvent.greenSample = ppgEvent->greenSample;
	max86161RightPPGEvent.irSample = ppgEvent->irSample;

	storeSamplePPGEarGreenRight(max86161RightPPGEvent.redSample);
	storeSamplePPGEarRedRight(max86161RightPPGEvent.greenSample);
	storeSamplePPGEarIRRight(max86161RightPPGEvent.irSample);

	//HAL_GPIO_TogglePin(GPIOI, GPIO_PIN_3);

	//printf("R: %u, G: %u, I: %u", max86161LeftPPGEvent.redSample, max86161LeftPPGEvent.greenSample, max86161LeftPPGEvent.irSample);

	if(max86161RightCounter < GRAPH_DOWNSAMPLING_VALUE) {
		max86161RightCounter++;
	} else {
		max86161RightCounter = 0;
		xQueueSendFromISR(earPPGRightGreenQueue, (void *)&max86161RightPPGEvent.greenSample, (TickType_t)0);
		xQueueSendFromISR(earPPGRightRedQueue, (void *)&max86161RightPPGEvent.redSample, (TickType_t)0);
		xQueueSendFromISR(earPPGRightIRQueue, (void *)&max86161RightPPGEvent.irSample, (TickType_t)0);
	}
}

void max86161RightPPGDataCallback(MAXM86161PPGData_t* ppgEvent) {
	max86161RightPPGDataHandler(ppgEvent);
	//max86161RightPPGDataHandler(ppgEvent);
}

void max86161LeftPPGDataCallbackHandler(MAXM86161PPGData_t* ppgEvent) {
	max86161LeftPPGEvent.redSample = ppgEvent->redSample;
	max86161LeftPPGEvent.greenSample = ppgEvent->greenSample;
	max86161LeftPPGEvent.irSample = ppgEvent->irSample;

	storeSamplePPGEarGreenLeft(max86161LeftPPGEvent.redSample);
	storeSamplePPGEarRedLeft(max86161LeftPPGEvent.greenSample);
	storeSamplePPGEarIRLeft(max86161LeftPPGEvent.irSample);

	if(max86161LeftCounter < GRAPH_DOWNSAMPLING_VALUE) {
		max86161LeftCounter++;
	} else {
		max86161LeftCounter = 0;
		xQueueSendFromISR(earPPGLeftGreenQueue, (void *)&max86161LeftPPGEvent.greenSample, (TickType_t)0);
		xQueueSendFromISR(earPPGLeftRedQueue, (void *)&max86161LeftPPGEvent.redSample, (TickType_t)0);
		xQueueSendFromISR(earPPGLeftIRQueue, (void *)&max86161LeftPPGEvent.irSample, (TickType_t)0);
	}
}

void max86161LeftPPGDataCallback(MAXM86161PPGData_t* ppgEvent) {
	max86161LeftPPGDataCallbackHandler(ppgEvent);
	//max86161LeftPPGDataCallbackHandler(ppgEvent);
}

void HAL_GPIO_EXTI_Callback(uint16_t pin) {
    if(pin == TOUCH_PIRQ_Pin) {
    	if(touchIRQBinarySemaphore != NULL) {
    		xSemaphoreGiveFromISR(touchIRQBinarySemaphore, pdTRUE);
    		portYIELD_FROM_ISR(pdTRUE);
    	}
    } else if(pin == MAX30003_INTB_Pin) {
    	if(max30003IRQBinarySemaphore != NULL) {
    		xSemaphoreGiveFromISR(max30003IRQBinarySemaphore, pdTRUE);
    		portYIELD_FROM_ISR(pdTRUE);
    	}
    } else if(pin == MAXM86161_LEFT_INT_Pin) {
    	if(maxm86161LeftIRQBinarySemaphore != NULL) {
    		xSemaphoreGiveFromISR(maxm86161LeftIRQBinarySemaphore, pdTRUE);
    		portYIELD_FROM_ISR(pdTRUE);
    	}
    } else if(pin == MAXM86161_RIGHT_INT_Pin) {
    	if(maxm86161RightIRQBinarySemaphore != NULL) {
    		xSemaphoreGiveFromISR(maxm86161RightIRQBinarySemaphore, pdTRUE);
    		portYIELD_FROM_ISR(pdTRUE);
    	}
    } else if(pin == MAX30102_INT_Pin) {
    	if(max30102IRQBinarySemaphore != NULL) {
    		xSemaphoreGiveFromISR(max30102IRQBinarySemaphore, pdTRUE);
    		portYIELD_FROM_ISR(pdTRUE);
    	}
    }
}

/* USER CODE END FunctionPrototypes */

void StartDefaultTask(void *argument);
void StartTouchTask(void *argument);
void StartTouchIRQTask(void *argument);
void StartMAX30003Task(void *argument);
void StartMAX30003IRQTask(void *argument);
void StartMAX30102Task(void *argument);
void StartMAX30102IRQTask(void *argument);
void StartMAXM86161RTask(void *argument);
void StartMAXM86161IRQRTask(void *argument);
void StartMAXM86161LTask(void *argument);
void StartMAXM86161IRQLTask(void *argument);
void StartI2C1TxTask(void *argument);
void StartI2C1RxTask(void *argument);
void StartI2C1ErrorTask(void *argument);
void StartI2C2TxTask(void *argument);
void StartI2C2RxTask(void *argument);
void StartI2C2ErrorTask(void *argument);
void StartDebugTask(void *argument);
void StartFatFsTask(void *argument);
void StartUsbTask(void *argument);
void StartUsbDmaTxTask(void *argument);
void StartUsbDmaRxTask(void *argument);
void StartI2C4TxTask(void *argument);
void StartI2C4RxTask(void *argument);
void StartI2C4ErrorTask(void *argument);
void StartTestTask(void *argument);

extern void MX_USB_DEVICE_Init(void);
void MX_FREERTOS_Init(void); /* (MISRA C 2004 rule 8.1) */

/* Hook prototypes */
void vApplicationIdleHook(void);
void vApplicationTickHook(void);
void vApplicationMallocFailedHook(void);
void vApplicationDaemonTaskStartupHook(void);

/* USER CODE BEGIN 2 */
void vApplicationIdleHook( void )
{
   /* vApplicationIdleHook() will only be called if configUSE_IDLE_HOOK is set
   to 1 in FreeRTOSConfig.h. It will be called on each iteration of the idle
   task. It is essential that code added to this hook function never attempts
   to block in any way (for example, call xQueueReceive() with a block time
   specified, or call vTaskDelay()). If the application makes use of the
   vTaskDelete() API function (as this demo application does) then it is also
   important that vApplicationIdleHook() is permitted to return to its calling
   function, because it is the responsibility of the idle task to clean up
   memory allocated by the kernel to any task that has since been deleted. */
}
/* USER CODE END 2 */

/* USER CODE BEGIN 3 */
void vApplicationTickHook( void )
{
   /* This function will be called by each tick interrupt if
   configUSE_TICK_HOOK is set to 1 in FreeRTOSConfig.h. User code can be
   added here, but the tick hook is called from an interrupt context, so
   code must not attempt to block, and only the interrupt safe FreeRTOS API
   functions can be used (those that end in FromISR()). */
}
/* USER CODE END 3 */

/* USER CODE BEGIN 5 */
void vApplicationMallocFailedHook(void)
{
   /* vApplicationMallocFailedHook() will only be called if
   configUSE_MALLOC_FAILED_HOOK is set to 1 in FreeRTOSConfig.h. It is a hook
   function that will get called if a call to pvPortMalloc() fails.
   pvPortMalloc() is called internally by the kernel whenever a task, queue,
   timer or semaphore is created. It is also called by various parts of the
   demo application. If heap_1.c or heap_2.c are used, then the size of the
   heap available to pvPortMalloc() is defined by configTOTAL_HEAP_SIZE in
   FreeRTOSConfig.h, and the xPortGetFreeHeapSize() API function can be used
   to query the size of free heap space that remains (although it does not
   provide information on how the remaining heap might be fragmented). */
}
/* USER CODE END 5 */

/* USER CODE BEGIN DAEMON_TASK_STARTUP_HOOK */
void vApplicationDaemonTaskStartupHook(void)
{
}
/* USER CODE END DAEMON_TASK_STARTUP_HOOK */

void MX_FREERTOS_Init(void) {
  /* USER CODE BEGIN Init */
  standartECGQueue = xQueueCreate( 10, sizeof(int));
  if(standartECGQueue == 0) {
	  printf("Can't create a queue");
  }

  earECGQueue = xQueueCreate( 50, sizeof(int));
  if(earECGQueue == 0) {
	  printf("Can't create a queue");
  }

  fingerPPGRedQueue = xQueueCreate( 50, sizeof(int));
  if(fingerPPGRedQueue == 0) {
	  printf("Can't create a queue");
  }

  fingerPPGIRQueue = xQueueCreate( 50, sizeof(int));
  if(fingerPPGIRQueue == 0) {
	  printf("Can't create a queue");
  }

  earPPGRightGreenQueue = xQueueCreate(100, sizeof(int));
  if(earPPGRightGreenQueue == 0) {
	printf("Can't create a queue");
  }

  earPPGRightRedQueue = xQueueCreate(100, sizeof(int));
  if(earPPGRightRedQueue == 0) {
	printf("Can't create a queue");
  }

  earPPGRightIRQueue = xQueueCreate(100, sizeof(int));
  if(earPPGRightIRQueue == 0) {
	printf("Can't create a queue");
  }

  earPPGLeftGreenQueue = xQueueCreate(100, sizeof(int));
  if(earPPGRightGreenQueue == 0) {
	printf("Can't create a queue");
  }

  earPPGLeftRedQueue = xQueueCreate(100, sizeof(int));
  if(earPPGRightRedQueue == 0) {
	printf("Can't create a queue");
  }

  earPPGLeftIRQueue = xQueueCreate(100, sizeof(int));
  if(earPPGRightIRQueue == 0) {
	printf("Can't create a queue");
  }

  i2c1TxBinarySemaphore = xSemaphoreCreateBinary();
  if(i2c1TxBinarySemaphore == NULL) {
	 printf("Can't create i2c1TxBinarySemaphore");
  }

  i2c1RxBinarySemaphore = xSemaphoreCreateBinary();
  if(i2c1RxBinarySemaphore == NULL) {
	 printf("Can't create i2c1RxBinarySemaphore");
  }

  i2c1ErrorBinarySemaphore = xSemaphoreCreateBinary();
  if(i2c1ErrorBinarySemaphore == NULL) {
	 printf("Can't create i2c1ErrorBinarySemaphore");
  }

  i2c2TxBinarySemaphore = xSemaphoreCreateBinary();
  if(i2c2TxBinarySemaphore == NULL) {
	 printf("Can't create i2c2TxBinarySemaphore");
  }

  i2c2RxBinarySemaphore = xSemaphoreCreateBinary();
  if(i2c2RxBinarySemaphore == NULL) {
	 printf("Can't create i2c2RxBinarySemaphore");
  }

  i2c2ErrorBinarySemaphore = xSemaphoreCreateBinary();
  if(i2c2ErrorBinarySemaphore == NULL) {
	 printf("Can't create i2c2ErrorBinarySemaphore");
  }

  i2c4TxBinarySemaphore = xSemaphoreCreateBinary();
  if(i2c2TxBinarySemaphore == NULL) {
	 printf("Can't create i2c4TxBinarySemaphore");
  }

  i2c4RxBinarySemaphore = xSemaphoreCreateBinary();
  if(i2c2RxBinarySemaphore == NULL) {
	 printf("Can't create i2c4RxBinarySemaphore");
  }

  i2c4ErrorBinarySemaphore = xSemaphoreCreateBinary();
  if(i2c2ErrorBinarySemaphore == NULL) {
	 printf("Can't create i2c4ErrorBinarySemaphore");
  }

  storeEcgBinarySemaphore = xSemaphoreCreateBinary();
  if(storeEcgBinarySemaphore == NULL) {
	 printf("Can't create storeEcgBinarySemaphore");
  }

  setDoubleBufferSemaphore(storeEcgBinarySemaphore);

  i2c1MutexSemaphore = xSemaphoreCreateMutex();
  if(i2c1MutexSemaphore == NULL) {
	 printf("Can't create i2c1MutexSemaphore");
  }

  i2c2MutexSemaphore = xSemaphoreCreateMutex();
  if(i2c2MutexSemaphore == NULL) {
	 printf("Can't create i2c2MutexSemaphore");
  }

  i2c4MutexSemaphore = xSemaphoreCreateMutex();
  if(i2c2MutexSemaphore == NULL) {
	 printf("Can't create i2c4MutexSemaphore");
  }

  max30102IRQBinarySemaphore = xSemaphoreCreateBinary();
  if(max30102IRQBinarySemaphore == NULL) {
	 printf("Can't create max30102IRQBinarySemaphore");
  }

  maxm86161LeftIRQBinarySemaphore = xSemaphoreCreateBinary();
  if(maxm86161LeftIRQBinarySemaphore == NULL) {
	 printf("Can't create maxm86161LeftIRQBinarySemaphore");
  }

  maxm86161RightIRQBinarySemaphore = xSemaphoreCreateBinary();
  if(maxm86161RightIRQBinarySemaphore == NULL) {
	 printf("Can't create maxm86161RightIRQBinarySemaphore");
  }

  touchIRQBinarySemaphore = xSemaphoreCreateBinary();
  if(touchIRQBinarySemaphore == NULL) {
	 printf("Can't create touchIRQBinarySemaphore");
  }

  max30003IRQBinarySemaphore = xSemaphoreCreateBinary();
  if(max30003IRQBinarySemaphore == NULL) {
	 printf("Can't create max30003IRQBinarySemaphore");
  }

  usbBinarySemaphore = xSemaphoreCreateBinary();
  usbDmaTxBinarySemaphore = xSemaphoreCreateBinary();
  usbDmaRxBinarySemaphore = xSemaphoreCreateBinary();

  testBinarySemaphore = xSemaphoreCreateBinary();

  fsMutexSemaphore = xSemaphoreCreateMutex();

  HAL_NVIC_SetPriority(EXTI1_IRQn, 10, 11);
  HAL_NVIC_EnableIRQ(EXTI1_IRQn);

  HAL_NVIC_SetPriority(EXTI2_IRQn, 10, 12);
  HAL_NVIC_EnableIRQ(EXTI2_IRQn);

  HAL_NVIC_SetPriority(EXTI3_IRQn, 10, 13);
  HAL_NVIC_EnableIRQ(EXTI3_IRQn);

  HAL_NVIC_SetPriority(EXTI4_IRQn, 10, 14);
  HAL_NVIC_EnableIRQ(EXTI4_IRQn);

  HAL_NVIC_SetPriority(EXTI9_5_IRQn, 10, 15);
  HAL_NVIC_EnableIRQ(EXTI9_5_IRQn);
  /* USER CODE END Init */

  /* Create the thread(s) */
  /* creation of defaultTask */
  defaultTaskHandle = osThreadNew(StartDefaultTask, NULL, &defaultTask_attributes);

  /* creation of touchTask */
  touchTaskHandle = osThreadNew(StartTouchTask, NULL, &touchTask_attributes);

  /* creation of touchIRQTask */
  touchIRQTaskHandle = osThreadNew(StartTouchIRQTask, NULL, &touchIRQTask_attributes);

  /* creation of max30003Task */
  max30003TaskHandle = osThreadNew(StartMAX30003Task, NULL, &max30003Task_attributes);

  /* creation of max30003IRQTask */
  max30003IRQTaskHandle = osThreadNew(StartMAX30003IRQTask, NULL, &max30003IRQTask_attributes);

  /* creation of i2c1TxTask */
  i2c1TxTaskHandle = osThreadNew(StartI2C1TxTask, NULL, &i2c1TxTask_attributes);

  /* creation of i2c1RxTask */
  i2c1RxTaskHandle = osThreadNew(StartI2C1RxTask, NULL, &i2c1RxTask_attributes);

  /* creation of i2c1ErrorTask */
  i2c1ErrorTaskHandle = osThreadNew(StartI2C1ErrorTask, NULL, &i2c1ErrorTask_attributes);

  /* creation of i2c2TxTask */
  i2c2TxTaskHandle = osThreadNew(StartI2C2TxTask, NULL, &i2c2TxTask_attributes);

  /* creation of i2c2RxTask */
  i2c2RxTaskHandle = osThreadNew(StartI2C2RxTask, NULL, &i2c2RxTask_attributes);

  /* creation of i2c2ErrorTask */
  i2c2ErrorTaskHandle = osThreadNew(StartI2C2ErrorTask, NULL, &i2c2ErrorTask_attributes);

  /* creation of i2c4TxTask */
  i2c4TxTaskHandle = osThreadNew(StartI2C4TxTask, NULL, &i2c4TxTask_attributes);

  /* creation of i2c4RxTask */
  i2c4RxTaskHandle = osThreadNew(StartI2C4RxTask, NULL, &i2c4RxTask_attributes);

  /* creation of i2c4ErrorTask */
  i2c4ErrorTaskHandle = osThreadNew(StartI2C4ErrorTask, NULL, &i2c4ErrorTask_attributes);

  /* creation of max30102Task */
  max30102TaskHandle = osThreadNew(StartMAX30102Task, NULL, &max30102Task_attributes);

  /* creation of max30102IRQTask */
  max30102IRQTaskHandle = osThreadNew(StartMAX30102IRQTask, NULL, &max30102IRQTask_attributes);

  /* creation of maxm86161RTask */
  maxm86161RTaskHandle = osThreadNew(StartMAXM86161RTask, NULL, &maxm86161RTask_attributes);

  /* creation of maxm86161IRTask */
  maxm86161IRTaskHandle = osThreadNew(StartMAXM86161IRQRTask, NULL, &maxm86161IRTask_attributes);

  /* creation of maxm86161LTask */
  maxm86161LTaskHandle = osThreadNew(StartMAXM86161LTask, NULL, &maxm86161LTask_attributes);

  /* creation of maxm86161ILTask */
  maxm86161ILTaskHandle = osThreadNew(StartMAXM86161IRQLTask, NULL, &maxm86161ILTask_attributes);

  /* creation of debugTask */
  //debugTaskHandle = osThreadNew(StartDebugTask, NULL, &debugTask_attributes);

  initRecordingUseCase(&currentFilename);
  /* creation of fatFsTask */
  fatFsTaskHandle = osThreadNew(StartFatFsTask, NULL, &fatFsTask_attributes);

  /* creation of usbTask */
  //usbTaskHandle = osThreadNew(StartUsbTask, NULL, &usbTask_attributes);

  /* creation of usbDmaTxTask */
  //usbDmaTxTaskHandle = osThreadNew(StartUsbDmaTxTask, NULL, &usbDmaTxTask_attributes);

  /* creation of usbDmaRxTask */
  //usbDmaRxTaskHandle = osThreadNew(StartUsbDmaRxTask, NULL, &usbDmaRxTask_attributes);

  //testTaskHandle = osThreadNew(StartTestTask, NULL, &testTask_attributes);

}

void StartDefaultTask(void *argument)
{
  /* init code for USB_DEVICE */
  //MX_USB_DEVICE_Init();
  /* USER CODE BEGIN StartDefaultTask */
  MX_TouchGFX_Process();
  /* Infinite loop */
  for(;;)
  {
    osDelay(1);
  }
  /* USER CODE END StartDefaultTask */
}

void StartTouchTask(void *argument)
{
  /* USER CODE BEGIN StartTouchTask */
  // Init touch controller here
  /* Infinite loop */
  for(;;)
  {
	osThreadSuspend(NULL);
    osDelay(1);
  }
  /* USER CODE END StartTouchTask */
}

void StartTouchIRQTask(void *argument)
{
  /* USER CODE BEGIN StartTouchIRQTask */
  /* Infinite loop */
  for(;;)
  {
	  if(xSemaphoreTake(touchIRQBinarySemaphore, 1) == pdTRUE) {
		  while(xpt2046Device.settings->readPenStateFunction()) {
			  xpt2046LowLevelPenInterruptBottomHalfHandler();
			  osDelay(50);
		  }
	  }
      osDelay(1);
  }
  /* USER CODE END StartTouchIRQTask */
}

void StartMAX30003Task(void *argument)
{
  /* USER CODE BEGIN StartMAX30003Task */
	osThreadSuspend(NULL);
	for (;;) {
		vTaskDelay(5);
		max30003LowLevelTick();
	}
  /* USER CODE END StartMAX30003Task */
}

void StartMAX30003IRQTask(void *argument)
{
  /* USER CODE BEGIN StartMAX30003IRQTask */
	max30003LowLevelInit(max30003ECGDataCallback);
	max30003Start(&max30003device);
	osThreadResume(max30003TaskHandle);
	for(;;)
	{
		if(xSemaphoreTake(max30003IRQBinarySemaphore, 1000) == pdTRUE) {
			//max30003LowLevelInterruptBottomHalfHandler();
		}
		vTaskDelay(1);
	}
  /* USER CODE END StartMAX30003IRQTask */
}

void StartMAX30102Task(void *argument)
{
  /* USER CODE BEGIN StartMAX30102Task */
	if(xSemaphoreTake(i2c4MutexSemaphore, 1000) == pdTRUE) {
		max30102LLInit(max30102PPGDataCallback);
		max30102Start(&max30102device);

		//vTaskDelay(50);
		//max30102LLTick();
		//vTaskDelay(50);
		//max30102LLTick();
		xSemaphoreGive(i2c4MutexSemaphore);
	} else {
		printf("Can't take i2c1MutexSemaphore\n");
	}
	for (;;) {
		vTaskDelay(50);
		if(xSemaphoreTake(i2c4MutexSemaphore, 1000) == pdTRUE) {
			max30102LLTick();
			xSemaphoreGive(i2c4MutexSemaphore);
		}
	}
  /* USER CODE END StartMAX30102Task */
}

void StartMAX30102IRQTask(void *argument)
{
  /* USER CODE BEGIN StartMAX30102IRQTask */
	for(;;)
	{
	  if(xSemaphoreTake(max30102IRQBinarySemaphore, 1000) == pdTRUE) {
		  if(xSemaphoreTake(i2c4MutexSemaphore, 1000) == pdTRUE) {
		  	  //max30102LLInterruptBottomHalfHandler();
		  	  xSemaphoreGive(i2c4MutexSemaphore);
	  	  }
	  }
	  vTaskDelay(1);
	}
  /* USER CODE END StartMAX30102IRQTask */
}

void StartMAXM86161RTask(void *argument)
{
  /* USER CODE BEGIN StartMAXM86161RTask */
	if(xSemaphoreTake(i2c2MutexSemaphore, 1000) == pdTRUE) {
		max86161RightLLInit(max86161RightPPGDataCallback);
		vTaskDelay(10);
		max86161Start(&max86161RightDevice);
		xSemaphoreGive(i2c2MutexSemaphore);
	}
	for (;;) {
		vTaskDelay(5);
		if(xSemaphoreTake(i2c2MutexSemaphore, 1000) == pdTRUE) {
			max86161RightLLTick();
			xSemaphoreGive(i2c2MutexSemaphore);
		}
	}
  /* USER CODE END StartMAXM86161RTask */
}

void StartMAXM86161IRQRTask(void *argument)
{
  /* USER CODE BEGIN StartMAXM86161IRQRTask */

	for(;;)
	{
		if(xSemaphoreTake(maxm86161RightIRQBinarySemaphore, 1000) == pdTRUE) {
			 if(xSemaphoreTake(i2c2MutexSemaphore, 1000) == pdTRUE) {
				 //max86161RightLLInterruptBottomHalfHandler();
				 xSemaphoreGive(i2c2MutexSemaphore);
			 }
		}
		vTaskDelay(1);
	}
  /* USER CODE END StartMAXM86161IRQRTask */
}

void StartMAXM86161LTask(void *argument)
{
  /* USER CODE BEGIN StartMAXM86161LTask */
	if(xSemaphoreTake(i2c1MutexSemaphore, 1000) == pdTRUE) {
		max86161LeftLLInit(max86161LeftPPGDataCallback);
		vTaskDelay(10);
		max86161Start(&max86161LeftDevice);
		xSemaphoreGive(i2c1MutexSemaphore);
	}

	for (;;) {
		vTaskDelay(5);
		if(xSemaphoreTake(i2c1MutexSemaphore, 1000) == pdTRUE) {
			max86161LeftLLTick();
			xSemaphoreGive(i2c1MutexSemaphore);
		}
	}
  /* USER CODE END StartMAXM86161LTask */
}

void StartMAXM86161IRQLTask(void *argument)
{
  /* USER CODE BEGIN StartMAXM86161IRQLTask */

	for(;;)
	{
		if(xSemaphoreTake(maxm86161LeftIRQBinarySemaphore, 1000) == pdTRUE) {
			 if(xSemaphoreTake(i2c1MutexSemaphore, 1000) == pdTRUE) {
				 	//max86161LeftLLInterruptBottomHalfHandler();
				 	xSemaphoreGive(i2c1MutexSemaphore);
	  		  }
	  	}
	  	vTaskDelay(1);
	}
  /* USER CODE END StartMAXM86161IRQLTask */
}

void StartI2C1TxTask(void *argument)
{
  /* USER CODE BEGIN StartI2C1TxTask */
	for( ;; ) {
		if(xSemaphoreTake(i2c1TxBinarySemaphore, 1000) == pdTRUE ) {
			if(xSemaphoreTake(i2c1MutexSemaphore, 1000) == pdTRUE) {
				max86161LLI2C1LeftTxHandler(&hi2c1);
				xSemaphoreGive(i2c1MutexSemaphore);
			}
		}
		vTaskDelay(1);
	}
  /* USER CODE END StartI2C1TxTask */
}

void StartI2C1RxTask(void *argument)
{
  /* USER CODE BEGIN StartI2C1RxTask */
	for( ;; ) {
		if(xSemaphoreTake(i2c1RxBinarySemaphore, 1000) == pdTRUE ) {
			if(xSemaphoreTake(i2c1MutexSemaphore, 1000) == pdTRUE) {
				max86161LLI2C1LeftRxHandler(&hi2c1);
				xSemaphoreGive(i2c1MutexSemaphore);
			}
		}
		vTaskDelay(1);
	}
  /* USER CODE END StartI2C1RxTask */
}

void StartI2C1ErrorTask(void *argument)
{
  /* USER CODE BEGIN StartI2C1ErrorTask */
	for( ;; ) {
		if(xSemaphoreTake(i2c1ErrorBinarySemaphore, 1000) == pdTRUE ) {
			if(xSemaphoreTake(i2c1MutexSemaphore, 1000) == pdTRUE) {
				max86161LLI2C1LeftErrorHandler(&hi2c1);
				xSemaphoreGive(i2c1MutexSemaphore);
			}
		}
		vTaskDelay(1);
	}
  /* USER CODE END StartI2C1ErrorTask */
}

void StartI2C2TxTask(void *argument)
{
  /* USER CODE BEGIN StartI2C2TxTask */
	for( ;; ) {
		if(xSemaphoreTake(i2c2TxBinarySemaphore, 1000) == pdTRUE ) {
			if(xSemaphoreTake(i2c2MutexSemaphore, 1000) == pdTRUE) {
				max86161LLI2C2RightTxHandler(&hi2c2);
				xSemaphoreGive(i2c2MutexSemaphore);
			}
		}
		vTaskDelay(1);
	}
  /* USER CODE END StartI2C2TxTask */
}

void StartI2C2RxTask(void *argument)
{
  /* USER CODE BEGIN StartI2C2RxTask */
	for( ;; ) {
		if(xSemaphoreTake(i2c2RxBinarySemaphore, 1000) == pdTRUE ) {
			if(xSemaphoreTake(i2c2MutexSemaphore, 1000) == pdTRUE) {
				max86161LLI2C2RightRxHandler(&hi2c2);
				xSemaphoreGive(i2c2MutexSemaphore);
			}
		}
		vTaskDelay(1);
	}
  /* USER CODE END StartI2C2RxTask */
}

void StartI2C2ErrorTask(void *argument)
{
  /* USER CODE BEGIN StartI2C2ErrorTask */
	for( ;; ) {
		if(xSemaphoreTake(i2c2ErrorBinarySemaphore, 1000) == pdTRUE ) {
			if(xSemaphoreTake(i2c2MutexSemaphore, 1000) == pdTRUE) {
				max86161LLI2C2RightErrorHandler(&hi2c2);
				xSemaphoreGive(i2c2MutexSemaphore);
			}
		}
		vTaskDelay(1);
	}
  /* USER CODE END StartI2C2ErrorTask */
}

void StartDebugTask(void *argument)
{
  /* USER CODE BEGIN StartDebugTask */
  /* Infinite loop */
  for(;;)
  {
		osDelay(10000);
	    vTaskList(debugInfoBuffer);
	    printf("Name\t\t\tState\tPriority\tStack\tNum\n%s", debugInfoBuffer);

  }
  /* USER CODE END StartDebugTask */
}

void StartFatFsTask(void *argument)
{
  /* USER CODE BEGIN StartFatFsTask */
	FIL MyFile;
	uint32_t totalFileBytes = 0;
	uint32_t writtenBytes = 0;
	//char currentLine[20] = {'\0'};
	FRESULT fresult = FR_OK;

	for (;;) {
		if(getRecordingStateUseCase() == RECORDING_STATE_STARTED) {
			if(BSP_PlatformIsDetected() == SD_PRESENT) {
				prebuildWritingBuffer();
				if(xSemaphoreTake(storeEcgBinarySemaphore, 100) == pdTRUE) {
					if(xSemaphoreTake(fsMutexSemaphore, 100) == pdTRUE) {
						//HAL_GPIO_WritePin(GPIOI, GPIO_PIN_3, GPIO_PIN_SET);
						if(retSD == 0) {
							fresult = f_mount(&SDFatFS, (TCHAR const*)SDPath, 0);
							if(fresult == FR_OK) {
								fresult = f_open(&MyFile, (char*)currentFilename, FA_OPEN_APPEND | FA_WRITE);
								if(fresult == FR_OK) {
									totalFileBytes = f_size(&MyFile);
									fresult = f_lseek(&MyFile, totalFileBytes);
									if(fresult == FR_OK) {
										char* bufferPointer = NULL;
										uint32_t stringLength = combineWritingBuffer(&bufferPointer);
										fresult = f_write(&MyFile, bufferPointer, stringLength, (void *)&writtenBytes);
										if(fresult == FR_OK) {
											printf("Written bytes: %lu, string length: %lu\n", writtenBytes, stringLength);
											/*
											fresult = f_sync(&MyFile);
											if(fresult == FR_OK) {

											} else {
												printf("Failed to sync a file\n");
												errorRecordingUseCase("SYNC FILE ERROR");
											}
											*/
											f_close(&MyFile);

										} else {
											printf("Can't write a file, fresult: %d\n", fresult);
											errorRecordingUseCase("WRITE FILE ERROR");
										}
										f_close(&MyFile);
									} else {
										printf("Failed to seek\n");
										errorRecordingUseCase("SEEK FILE ERROR");
									}

								} else {
									printf("Can't open a file, fresult: %d\n", fresult);
									errorRecordingUseCase("OPEN FILE ERROR");
								}

								fresult = f_mount(NULL, (TCHAR const*)SDPath, 1);
								if(fresult == FR_OK) {

								} else {
									printf("Umount failed\n");
									errorRecordingUseCase("SDCARD UNMOUNT ERROR");
								}
							} else {
								printf("Can't mount a SD card, fresult: %d\n", fresult);
								errorRecordingUseCase("SDCARD MOUNT ERROR");
							}
						} else {
							printf("Can't link a driver!\n");
							errorRecordingUseCase("SDCARD DRIVER ERROR");
						}
						//HAL_GPIO_WritePin(GPIOI, GPIO_PIN_3, GPIO_PIN_RESET);
						xSemaphoreGive(fsMutexSemaphore);
					}
				}
			} else {
				errorRecordingUseCase("NO SDCARD!");
			}
		}
		vTaskDelay(1);
	}
  /* USER CODE END StartFatFsTask */
}

void StartUsbTask(void *argument)
{
  /* USER CODE BEGIN StartUsbTask */
	MX_USB_DEVICE_Init();
	for( ;; ) {
		/*
		if(xSemaphoreTake(usbBinarySemaphore, 1000) == pdTRUE ) {
			if(xSemaphoreTake(fsMutexSemaphore, 1000) == pdTRUE) {
				HAL_PCD_IRQHandler(&hpcd_USB_OTG_FS);
				xSemaphoreGive(fsMutexSemaphore);
			}
			HAL_NVIC_EnableIRQ(OTG_FS_IRQn);
		}
		*/
		vTaskDelay(1);
	}
  /* USER CODE END StartUsbTask */
}

void StartUsbDmaTxTask(void *argument)
{
  /* USER CODE BEGIN StartUsbDmaTxTask */
	for( ;; ) {
		if(xSemaphoreTake(usbDmaTxBinarySemaphore, 1000) == pdTRUE ) {
		//	if(xSemaphoreTake(fsMutexSemaphore, 1000) == pdTRUE) {
				HAL_DMA_IRQHandler(&hdma_sdio_tx);
				//xSemaphoreGive(fsMutexSemaphore);
		//	}
		}
	}
  /* USER CODE END StartUsbDmaTxTask */
}

void StartUsbDmaRxTask(void *argument)
{
  /* USER CODE BEGIN StartUsbDmaRxTask */
	for( ;; ) {
		if(xSemaphoreTake(usbDmaRxBinarySemaphore, 1000) == pdTRUE ) {
		//	if(xSemaphoreTake(fsMutexSemaphore, 1000) == pdTRUE) {
				HAL_DMA_IRQHandler(&hdma_sdio_rx);
		//		xSemaphoreGive(fsMutexSemaphore);
		//	}
		}
	}
  /* USER CODE END StartUsbDmaRxTask */
}

void StartI2C4TxTask(void *argument)
{
  /* USER CODE BEGIN StartI2C4TxTask */
  /* Infinite loop */
  for(;;)
  {
	  if(xSemaphoreTake(i2c4TxBinarySemaphore, 1000) == pdTRUE ) {
		  if(xSemaphoreTake(i2c4MutexSemaphore, 1000) == pdTRUE) {
			  max30102LLI2CTxHandler(&hi2c1);
	  	  	  xSemaphoreGive(i2c4MutexSemaphore);
		  }
	  }
	  osDelay(1);
  }
  /* USER CODE END StartI2C4TxTask */
}

void StartI2C4RxTask(void *argument)
{
  /* USER CODE BEGIN StartI2C4RxTask */
  /* Infinite loop */
  for(;;)
  {
	  if(xSemaphoreTake(i2c4RxBinarySemaphore, 1000) == pdTRUE ) {
		  if(xSemaphoreTake(i2c4MutexSemaphore, 1000) == pdTRUE) {
			  max30102LLI2CRxHandler(&hi2c1);
			  xSemaphoreGive(i2c4MutexSemaphore);
		  }
	  }
	  osDelay(1);
  }
  /* USER CODE END StartI2C4RxTask */
}

void StartI2C4ErrorTask(void *argument)
{
  /* USER CODE BEGIN StartI2C4ErrorTask */
  /* Infinite loop */
  for(;;)
  {
	  if(xSemaphoreTake(i2c4ErrorBinarySemaphore, 1000) == pdTRUE ) {
		  if(xSemaphoreTake(i2c4MutexSemaphore, 1000) == pdTRUE) {
			  max30102LLI2CErrorHandler(&hi2c4);
			  xSemaphoreGive(i2c4MutexSemaphore);
		  }
	  }
	  osDelay(1);
  }
  /* USER CODE END StartI2C4ErrorTask */
}

/* USER CODE BEGIN Application */
void StartTestTask(void *argument)
{
  /* USER CODE BEGIN StartI2C4ErrorTask */
  /* Infinite loop */
  for(;;)
  {
	  if(getRecordingStateUseCase() != RECORDING_STATE_STARTED) {
		  if(xSemaphoreTake(testBinarySemaphore, 1000) == pdTRUE ) {
			  sdcardTestingUseCase(512);
			  vTaskDelay(1000);
			  sdcardTestingUseCase(1024);
			  vTaskDelay(1000);
			  sdcardTestingUseCase(2048);
			  vTaskDelay(1000);
			  sdcardTestingUseCase(4096);
			  vTaskDelay(1000);
			  sdcardTestingUseCase(1000);
			  vTaskDelay(1000);
			  sdcardTestingUseCase(2000);
			  vTaskDelay(1000);
			  sdcardTestingUseCase(3000);
			  vTaskDelay(1000);
			  sdcardTestingUseCase(4000);
			  completeTestingUseCase();
		  }
	  }
	  osDelay(100);
  }
  /* USER CODE END StartI2C4ErrorTask */
}
/* USER CODE END Application */

/************************ (C) COPYRIGHT STMicroelectronics *****END OF FILE****/
